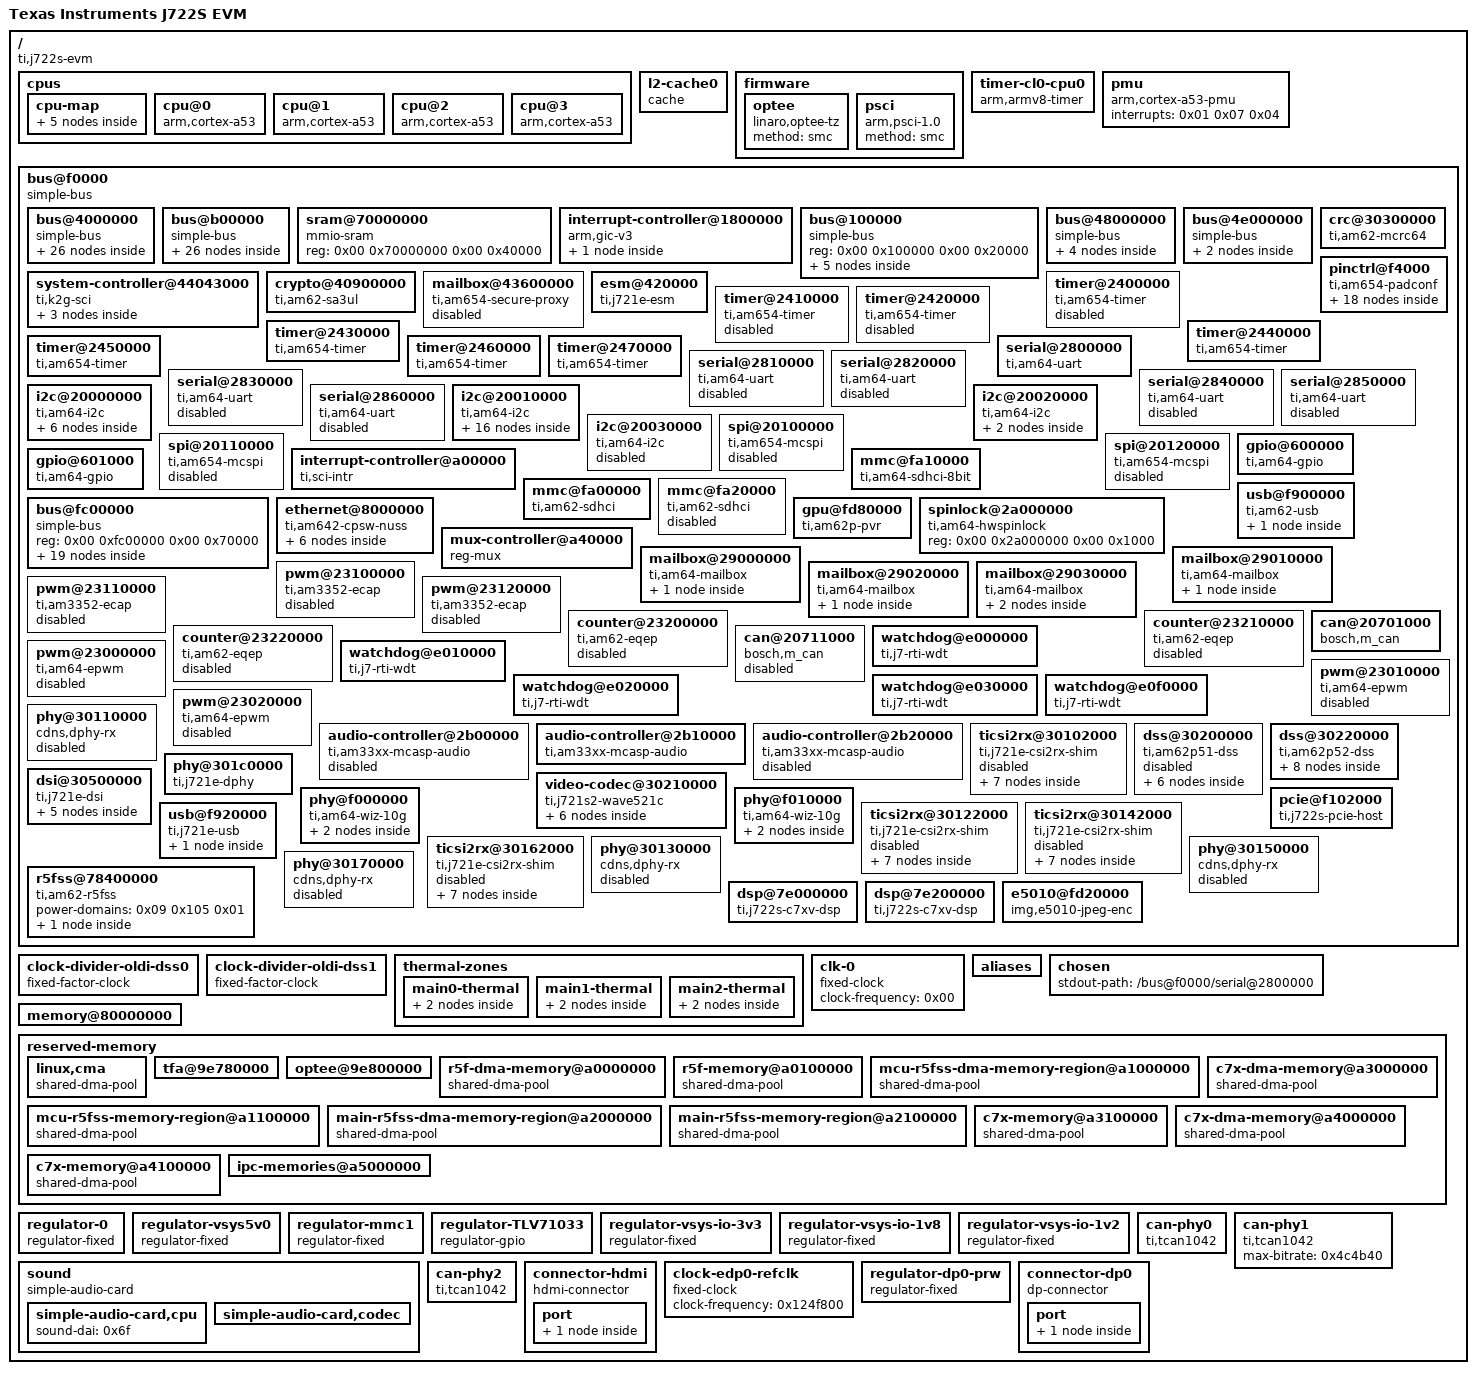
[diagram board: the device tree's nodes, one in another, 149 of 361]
/dts-v1/;

/ {
	model = "Texas Instruments J722S EVM";
	compatible = "ti,j722s-evm\0ti,j722s";
	interrupt-parent = <0x01>;
	#address-cells = <0x02>;
	#size-cells = <0x02>;

	cpus {
		#address-cells = <0x01>;
		#size-cells = <0x00>;

		cpu-map {

			cluster0 {
				phandle = <0x77>;

				core0 {
					cpu = <0x02>;
				};

				core1 {
					cpu = <0x03>;
				};

				core2 {
					cpu = <0x04>;
				};

				core3 {
					cpu = <0x05>;
				};
			};
		};

		cpu@0 {
			compatible = "arm,cortex-a53";
			reg = <0x00>;
			device_type = "cpu";
			enable-method = "psci";
			i-cache-size = <0x8000>;
			i-cache-line-size = <0x40>;
			i-cache-sets = <0x100>;
			d-cache-size = <0x8000>;
			d-cache-line-size = <0x40>;
			d-cache-sets = <0x80>;
			next-level-cache = <0x06>;
			clocks = <0x07 0x87 0x00>;
			phandle = <0x02>;
		};

		cpu@1 {
			compatible = "arm,cortex-a53";
			reg = <0x01>;
			device_type = "cpu";
			enable-method = "psci";
			i-cache-size = <0x8000>;
			i-cache-line-size = <0x40>;
			i-cache-sets = <0x100>;
			d-cache-size = <0x8000>;
			d-cache-line-size = <0x40>;
			d-cache-sets = <0x80>;
			next-level-cache = <0x06>;
			clocks = <0x07 0x88 0x00>;
			phandle = <0x03>;
		};

		cpu@2 {
			compatible = "arm,cortex-a53";
			reg = <0x02>;
			device_type = "cpu";
			enable-method = "psci";
			i-cache-size = <0x8000>;
			i-cache-line-size = <0x40>;
			i-cache-sets = <0x100>;
			d-cache-size = <0x8000>;
			d-cache-line-size = <0x40>;
			d-cache-sets = <0x80>;
			next-level-cache = <0x06>;
			clocks = <0x07 0x89 0x00>;
			phandle = <0x04>;
		};

		cpu@3 {
			compatible = "arm,cortex-a53";
			reg = <0x03>;
			device_type = "cpu";
			enable-method = "psci";
			i-cache-size = <0x8000>;
			i-cache-line-size = <0x40>;
			i-cache-sets = <0x100>;
			d-cache-size = <0x8000>;
			d-cache-line-size = <0x40>;
			d-cache-sets = <0x80>;
			next-level-cache = <0x06>;
			clocks = <0x07 0x8a 0x00>;
			phandle = <0x05>;
		};
	};

	l2-cache0 {
		compatible = "cache";
		cache-unified;
		cache-level = <0x02>;
		cache-size = <0x80000>;
		cache-line-size = <0x40>;
		cache-sets = <0x200>;
		phandle = <0x06>;
	};

	firmware {

		optee {
			compatible = "linaro,optee-tz";
			method = "smc";
		};

		psci {
			compatible = "arm,psci-1.0";
			method = "smc";
			phandle = <0x78>;
		};
	};

	timer-cl0-cpu0 {
		compatible = "arm,armv8-timer";
		interrupts = <0x01 0x0d 0x08 0x01 0x0e 0x08 0x01 0x0b 0x08 0x01 0x0a 0x08>;
		phandle = <0x79>;
	};

	pmu {
		compatible = "arm,cortex-a53-pmu";
		interrupts = <0x01 0x07 0x04>;
		phandle = <0x7a>;
	};

	bus@f0000 {
		compatible = "simple-bus";
		#address-cells = <0x02>;
		#size-cells = <0x02>;
		ranges = <0x00 0xf0000 0x00 0xf0000 0x00 0x30000 0x00 0x420000 0x00 0x420000 0x00 0x1000 0x00 0x600000 0x00 0x600000 0x00 0x1100 0x00 0x703000 0x00 0x703000 0x00 0x200 0x00 0x70c000 0x00 0x70c000 0x00 0x200 0x00 0xa40000 0x00 0xa40000 0x00 0x800 0x00 0x1000000 0x00 0x1000000 0x00 0x1b28400 0x00 0x8000000 0x00 0x8000000 0x00 0x200000 0x00 0xd000000 0x00 0xd000000 0x00 0x800000 0x00 0xe000000 0x00 0xe000000 0x00 0x1d20000 0x00 0xfd80000 0x00 0xfd80000 0x00 0x80000 0x00 0xfd20000 0x00 0xfd20000 0x00 0x100 0x00 0xfd20200 0x00 0xfd20200 0x00 0x200 0x00 0x20000000 0x00 0x20000000 0x00 0xa008000 0x00 0x30040000 0x00 0x30040000 0x00 0x80000 0x00 0x301c0000 0x00 0x301c0000 0x00 0x1000 0x00 0x30101000 0x00 0x30101000 0x00 0x80100 0x00 0x30200000 0x00 0x30200000 0x00 0x10000 0x00 0x30210000 0x00 0x30210000 0x00 0x10000 0x00 0x30220000 0x00 0x30220000 0x00 0x10000 0x00 0x30270000 0x00 0x30270000 0x00 0x10000 0x00 0x30300000 0x00 0x30300000 0x00 0x1000 0x00 0x30500000 0x00 0x30500000 0x00 0x100000 0x00 0x31000000 0x00 0x31000000 0x00 0x50000 0x00 0x31200000 0x00 0x31200000 0x00 0x40000 0x00 0x40900000 0x00 0x40900000 0x00 0x30000 0x00 0x43600000 0x00 0x43600000 0x00 0x10000 0x00 0x44043000 0x00 0x44043000 0x00 0xfe0 0x00 0x44860000 0x00 0x44860000 0x00 0x40000 0x00 0x48000000 0x00 0x48000000 0x00 0x6408000 0x00 0x60000000 0x00 0x60000000 0x00 0x8000000 0x00 0x68000000 0x00 0x68000000 0x00 0x8000000 0x00 0x70000000 0x00 0x70000000 0x00 0x40000 0x00 0x78400000 0x00 0x78400000 0x00 0x8000 0x00 0x78500000 0x00 0x78500000 0x00 0x8000 0x00 0x7e000000 0x00 0x7e000000 0x00 0x200000 0x00 0x7e200000 0x00 0x7e200000 0x00 0x200000 0x01 0x00 0x01 0x00 0x00 0x310000 0x05 0x00 0x05 0x00 0x01 0x00 0x06 0x00 0x06 0x00 0x01 0x00 0x00 0x4000000 0x00 0x4000000 0x00 0x1ff1400 0x00 0x79000000 0x00 0x79000000 0x00 0x8000 0x00 0x79020000 0x00 0x79020000 0x00 0x8000 0x00 0x79100000 0x00 0x79100000 0x00 0x40000 0x00 0x79140000 0x00 0x79140000 0x00 0x40000 0x00 0xb00000 0x00 0xb00000 0x00 0x2400 0x00 0x2b000000 0x00 0x2b000000 0x00 0x300400 0x00 0x43000000 0x00 0x43000000 0x00 0x20000 0x00 0x78000000 0x00 0x78000000 0x00 0x8000 0x00 0x78100000 0x00 0x78100000 0x00 0x8000>;
		phandle = <0x7b>;

		bus@4000000 {
			compatible = "simple-bus";
			#address-cells = <0x02>;
			#size-cells = <0x02>;
			ranges = <0x00 0x4000000 0x00 0x4000000 0x00 0x1ff1400 0x00 0x79000000 0x00 0x79000000 0x00 0x8000 0x00 0x79020000 0x00 0x79020000 0x00 0x8000 0x00 0x79100000 0x00 0x79100000 0x00 0x40000 0x00 0x79140000 0x00 0x79140000 0x00 0x40000>;
			bootph-all;
			phandle = <0x7c>;

			sram@79100000 {
				compatible = "mmio-sram";
				reg = <0x00 0x79100000 0x00 0x80000>;
				ranges = <0x00 0x00 0x79100000 0x80000>;
				#address-cells = <0x01>;
				#size-cells = <0x01>;
				phandle = <0x13>;

				mcu_sram1@0 {
					reg = <0x00 0x80000>;
				};
			};

			pinctrl@4084000 {
				compatible = "pinctrl-single";
				reg = <0x00 0x4084000 0x00 0x88>;
				#pinctrl-cells = <0x01>;
				pinctrl-single,register-width = <0x20>;
				pinctrl-single,function-mask = <0xffffffff>;
				pinctrl-single,gpio-range = <0x08 0x00 0x15 0x54007 0x08 0x17 0x01 0x54007 0x08 0x20 0x02 0x54007>;
				bootph-all;
				phandle = <0x0d>;

				gpio-range {
					#pinctrl-single,gpio-range-cells = <0x03>;
					phandle = <0x08>;
				};

				mcu-i2c0-default-pins {
					pinctrl-single,pins = <0x48 0x54000 0x44 0x54000>;
					phandle = <0x0a>;
				};

				mcu-mcan0-default-pins {
					pinctrl-single,pins = <0x38 0x54000 0x34 0x10000>;
					phandle = <0x0e>;
				};

				mcu-mcan1-default-pins {
					pinctrl-single,pins = <0x40 0x54000 0x3c 0x10000>;
					phandle = <0x10>;
				};

				mcu-mcan0-gpio-default-pins {
					pinctrl-single,pins = <0x30 0x10007>;
					phandle = <0x72>;
				};

				wkup-uart0-default-pins {
					pinctrl-single,pins = <0x2c 0x54000 0x30 0x10000 0x24 0x54000 0x28 0x10000>;
					bootph-all;
					phandle = <0x18>;
				};

				wkup-i2c0-default-pins {
					pinctrl-single,pins = <0x4c 0x64000 0x50 0x64000>;
					bootph-all;
					phandle = <0x19>;
				};
			};

			esm@4100000 {
				compatible = "ti,j721e-esm";
				reg = <0x00 0x4100000 0x00 0x1000>;
				bootph-pre-ram;
				ti,esm-pins = <0x00 0x01 0x02 0x55 0x56>;
				phandle = <0x7d>;
			};

			timer@4800000 {
				compatible = "ti,am654-timer";
				reg = <0x00 0x4800000 0x00 0x400>;
				clocks = <0x07 0x23 0x02>;
				clock-names = "fck";
				power-domains = <0x09 0x23 0x01>;
				ti,timer-pwm;
				status = "reserved";
				phandle = <0x7e>;
			};

			timer@4810000 {
				compatible = "ti,am654-timer";
				reg = <0x00 0x4810000 0x00 0x400>;
				clocks = <0x07 0x30 0x02>;
				clock-names = "fck";
				power-domains = <0x09 0x30 0x01>;
				ti,timer-pwm;
				status = "reserved";
				phandle = <0x7f>;
			};

			timer@4820000 {
				compatible = "ti,am654-timer";
				reg = <0x00 0x4820000 0x00 0x400>;
				clocks = <0x07 0x31 0x02>;
				clock-names = "fck";
				power-domains = <0x09 0x31 0x01>;
				ti,timer-pwm;
				status = "reserved";
				phandle = <0x80>;
			};

			timer@4830000 {
				compatible = "ti,am654-timer";
				reg = <0x00 0x4830000 0x00 0x400>;
				clocks = <0x07 0x32 0x02>;
				clock-names = "fck";
				power-domains = <0x09 0x32 0x01>;
				ti,timer-pwm;
				status = "reserved";
				phandle = <0x81>;
			};

			serial@4a00000 {
				compatible = "ti,am64-uart\0ti,am654-uart";
				reg = <0x00 0x4a00000 0x00 0x100>;
				interrupts = <0x00 0xb9 0x04>;
				power-domains = <0x09 0x95 0x01>;
				clocks = <0x07 0x95 0x00>;
				clock-names = "fclk";
				status = "disabled";
				phandle = <0x82>;
			};

			i2c@4900000 {
				compatible = "ti,am64-i2c\0ti,omap4-i2c";
				reg = <0x00 0x4900000 0x00 0x100>;
				interrupts = <0x00 0x6b 0x04>;
				#address-cells = <0x01>;
				#size-cells = <0x00>;
				power-domains = <0x09 0x6a 0x01>;
				clocks = <0x07 0x6a 0x02>;
				clock-names = "fck";
				status = "okay";
				pinctrl-names = "default";
				pinctrl-0 = <0x0a>;
				clock-frequency = <0x61a80>;
				phandle = <0x83>;
			};

			spi@4b00000 {
				compatible = "ti,am654-mcspi\0ti,omap4-mcspi";
				reg = <0x00 0x4b00000 0x00 0x400>;
				interrupts = <0x00 0xb0 0x04>;
				#address-cells = <0x01>;
				#size-cells = <0x00>;
				power-domains = <0x09 0x93 0x01>;
				clocks = <0x07 0x93 0x00>;
				status = "disabled";
				phandle = <0x84>;
			};

			spi@4b10000 {
				compatible = "ti,am654-mcspi\0ti,omap4-mcspi";
				reg = <0x00 0x4b10000 0x00 0x400>;
				interrupts = <0x00 0xb1 0x04>;
				#address-cells = <0x01>;
				#size-cells = <0x00>;
				power-domains = <0x09 0x94 0x01>;
				clocks = <0x07 0x94 0x00>;
				status = "disabled";
				phandle = <0x85>;
			};

			interrupt-controller@4210000 {
				compatible = "ti,sci-intr";
				reg = <0x00 0x4210000 0x00 0x200>;
				ti,intr-trigger-type = <0x01>;
				interrupt-controller;
				interrupt-parent = <0x01>;
				#interrupt-cells = <0x01>;
				ti,sci = <0x0b>;
				ti,sci-dev-id = <0x05>;
				ti,interrupt-ranges = <0x00 0x68 0x04>;
				phandle = <0x0c>;
			};

			gpio@4201000 {
				compatible = "ti,am64-gpio\0ti,keystone-gpio";
				reg = <0x00 0x4201000 0x00 0x100>;
				gpio-controller;
				#gpio-cells = <0x02>;
				interrupt-parent = <0x0c>;
				interrupts = <0x1e 0x1f>;
				interrupt-controller;
				#interrupt-cells = <0x02>;
				ti,ngpio = <0x18>;
				ti,davinci-gpio-unbanked = <0x00>;
				power-domains = <0x09 0x4f 0x01>;
				clocks = <0x07 0x4f 0x00>;
				clock-names = "gpio";
				gpio-ranges = <0x0d 0x00 0x00 0x15 0x0d 0x15 0x17 0x01 0x0d 0x16 0x20 0x02>;
				status = "okay";
				phandle = <0x73>;
			};

			watchdog@4880000 {
				compatible = "ti,j7-rti-wdt";
				reg = <0x00 0x4880000 0x00 0x100>;
				clocks = <0x07 0x83 0x00>;
				power-domains = <0x09 0x83 0x01>;
				assigned-clocks = <0x07 0x83 0x00>;
				assigned-clock-parents = <0x07 0x83 0x04>;
				status = "reserved";
				phandle = <0x86>;
			};

			can@4e08000 {
				compatible = "bosch,m_can";
				reg = <0x00 0x4e08000 0x00 0x200 0x00 0x4e00000 0x00 0x8000>;
				reg-names = "m_can\0message_ram";
				power-domains = <0x09 0xbc 0x01>;
				clocks = <0x07 0xbc 0x06 0x07 0xbc 0x01>;
				clock-names = "hclk\0cclk";
				bosch,mram-cfg = <0x00 0x80 0x40 0x40 0x40 0x40 0x20 0x20>;
				interrupts = <0x00 0x1a 0x04 0x00 0x1b 0x04>;
				interrupt-names = "int0\0int1";
				wakeup-source = "suspend\0poweroff";
				status = "okay";
				pinctrl-names = "default";
				pinctrl-0 = <0x0e>;
				phys = <0x0f>;
				phandle = <0x87>;
			};

			can@4e18000 {
				compatible = "bosch,m_can";
				reg = <0x00 0x4e18000 0x00 0x200 0x00 0x4e10000 0x00 0x8000>;
				reg-names = "m_can\0message_ram";
				power-domains = <0x09 0xbd 0x01>;
				clocks = <0x07 0xbd 0x06 0x07 0xbd 0x01>;
				clock-names = "hclk\0cclk";
				bosch,mram-cfg = <0x00 0x80 0x40 0x40 0x40 0x40 0x20 0x20>;
				interrupts = <0x00 0x1c 0x04 0x00 0x1d 0x04>;
				interrupt-names = "int0\0int1";
				wakeup-source = "suspend\0poweroff";
				status = "okay";
				pinctrl-names = "default";
				pinctrl-0 = <0x10>;
				phys = <0x11>;
				phandle = <0x88>;
			};

			r5fss@79000000 {
				compatible = "ti,am62-r5fss";
				#address-cells = <0x01>;
				#size-cells = <0x01>;
				ranges = <0x79000000 0x00 0x79000000 0x8000 0x79020000 0x00 0x79020000 0x8000>;
				power-domains = <0x09 0x07 0x01>;
				status = "disabled";
				phandle = <0x89>;

				r5f@79000000 {
					compatible = "ti,am62-r5f";
					reg = <0x79000000 0x8000 0x79020000 0x8000>;
					reg-names = "atcm\0btcm";
					ti,sci = <0x0b>;
					ti,sci-dev-id = <0x09>;
					ti,sci-proc-ids = <0x03 0xff>;
					resets = <0x12 0x09 0x01>;
					firmware-name = "j722s-mcu-r5f0_0-fw";
					ti,atcm-enable = <0x00>;
					ti,btcm-enable = <0x01>;
					ti,loczrama = <0x00>;
					sram = <0x13>;
					status = "disabled";
					mboxes = <0x14 0x15>;
					memory-region = <0x16 0x17>;
					phandle = <0x8a>;
				};
			};
		};

		bus@b00000 {
			compatible = "simple-bus";
			#address-cells = <0x02>;
			#size-cells = <0x02>;
			ranges = <0x00 0xb00000 0x00 0xb00000 0x00 0x2400 0x00 0x2b000000 0x00 0x2b000000 0x00 0x300400 0x00 0x43000000 0x00 0x43000000 0x00 0x20000 0x00 0x78000000 0x00 0x78000000 0x00 0x8000 0x00 0x78100000 0x00 0x78100000 0x00 0x8000>;
			bootph-all;
			phandle = <0x8b>;

			bus@43000000 {
				compatible = "simple-bus";
				reg = <0x00 0x43000000 0x00 0x20000>;
				#address-cells = <0x01>;
				#size-cells = <0x01>;
				ranges = <0x00 0x00 0x43000000 0x20000>;
				bootph-all;
				phandle = <0x8c>;

				chipid@14 {
					compatible = "ti,am654-chipid";
					reg = <0x14 0x04>;
					bootph-all;
					phandle = <0x8d>;
				};

				syscon@18 {
					compatible = "ti,am62-opp-efuse-table\0syscon";
					reg = <0x18 0x04>;
					phandle = <0x8e>;
				};

				ethernet-mac-syscon@200 {
					compatible = "ti,am62p-cpsw-mac-efuse\0syscon";
					reg = <0x200 0x08>;
					phandle = <0x40>;
				};

				syscon@4008 {
					compatible = "ti,am62-usb-phy-ctrl\0syscon";
					reg = <0x4008 0x04>;
					phandle = <0x3c>;
				};

				syscon@4018 {
					compatible = "ti,am62-usb-phy-ctrl\0syscon";
					reg = <0x4018 0x04>;
					phandle = <0x8f>;
				};

				syscon@80d0 {
					compatible = "ti,am62-ddr-pmctrl\0syscon";
					reg = <0x80d0 0x04>;
					phandle = <0x90>;
				};

				syscon@18300 {
					compatible = "ti,am62-canuart-wake\0syscon";
					reg = <0x18300 0x44>;
					phandle = <0x91>;
				};

				pcie0-ctrl@4070 {
					compatible = "ti,j784s4-pcie-ctrl\0syscon";
					reg = <0x4070 0x04>;
					phandle = <0x56>;
				};
			};

			target-module@2b300050 {
				compatible = "ti,sysc-omap2\0ti,sysc";
				reg = <0x00 0x2b300050 0x00 0x04 0x00 0x2b300054 0x00 0x04 0x00 0x2b300058 0x00 0x04>;
				reg-names = "rev\0sysc\0syss";
				ti,sysc-mask = <0x07>;
				ti,sysc-sidle = <0x00 0x01 0x02 0x03>;
				ti,syss-mask = <0x01>;
				ti,no-reset-on-init;
				power-domains = <0x09 0x72 0x01>;
				clocks = <0x07 0x72 0x00>;
				clock-names = "fck";
				#address-cells = <0x01>;
				#size-cells = <0x01>;
				ranges = <0x00 0x00 0x2b300000 0x100000>;

				serial@0 {
					compatible = "ti,am64-uart\0ti,am654-uart";
					reg = <0x00 0x100>;
					interrupts = <0x00 0xba 0x04>;
					status = "reserved";
					pinctrl-names = "default";
					pinctrl-0 = <0x18>;
					bootph-all;
					phandle = <0x92>;
				};
			};

			i2c@2b200000 {
				compatible = "ti,am64-i2c\0ti,omap4-i2c";
				reg = <0x00 0x2b200000 0x00 0x100>;
				interrupts = <0x00 0xa5 0x04>;
				#address-cells = <0x01>;
				#size-cells = <0x00>;
				power-domains = <0x09 0x6b 0x01>;
				clocks = <0x07 0x6b 0x04>;
				clock-names = "fck";
				status = "okay";
				pinctrl-names = "default";
				pinctrl-0 = <0x19>;
				clock-frequency = <0x61a80>;
				bootph-all;
				phandle = <0x93>;

				pmic@48 {
					compatible = "ti,tps65224-q1";
					reg = <0x48>;
					pinctrl-names = "default";
					pinctrl-0 = <0x1a>;
					interrupt-parent = <0x1b>;
					interrupts = <0x00 0x02>;
					ti,primary-pmic;
					gpio-controller;
					#gpio-cells = <0x02>;
					buck12-supply = <0x1c>;
					buck3-supply = <0x1c>;
					buck4-supply = <0x1c>;
					ldo1-supply = <0x1c>;
					ldo2-supply = <0x1c>;
					ldo3-supply = <0x1c>;
					phandle = <0x94>;

					regulators {

						buck1 {
							regulator-name = "vcc1v8_io_buck1";
							regulator-min-microvolt = <0x1b7740>;
							regulator-max-microvolt = <0x1b7740>;
							regulator-boot-on;
							regulator-always-on;
							bootph-all;
							phandle = <0x95>;
						};

						buck2 {
							regulator-name = "vcc1v1_ddr_buck2";
							regulator-min-microvolt = <0x10c8e0>;
							regulator-max-microvolt = <0x10c8e0>;
							regulator-boot-on;
							regulator-always-on;
							phandle = <0x96>;
						};

						buck3 {
							regulator-name = "vcc0v85_ram_buck3";
							regulator-min-microvolt = <0xcf850>;
							regulator-max-microvolt = <0xcf850>;
							regulator-boot-on;
							regulator-always-on;
							phandle = <0x97>;
						};

						buck4 {
							regulator-name = "vcc0v75_ioret_buck4";
							regulator-min-microvolt = <0xb71b0>;
							regulator-max-microvolt = <0xb71b0>;
							regulator-boot-on;
							regulator-always-on;
							phandle = <0x98>;
						};

						ldo1 {
							regulator-name = "vdda1v8_pll_ldo1";
							regulator-min-microvolt = <0x1b7740>;
							regulator-max-microvolt = <0x1b7740>;
							regulator-boot-on;
							regulator-always-on;
							phandle = <0x99>;
						};

						ldo2 {
							regulator-name = "dvdd3v3_ldo2";
							regulator-min-microvolt = <0x325aa0>;
							regulator-max-microvolt = <0x325aa0>;
							regulator-boot-on;
							regulator-always-on;
							phandle = <0x9a>;
						};

						ldo3 {
							regulator-name = "vdd1v85_phy_ldo3";
							regulator-min-microvolt = <0x1b7740>;
							regulator-max-microvolt = <0x1b7740>;
							regulator-boot-on;
							regulator-always-on;
							phandle = <0x9b>;
						};
					};
				};
			};

			rtc@2b1f0000 {
				compatible = "ti,am62-rtc";
				reg = <0x00 0x2b1f0000 0x00 0x100>;
				interrupts = <0x00 0x64 0x04>;
				clocks = <0x07 0x75 0x06 0x07 0x75 0x00>;
				clock-names = "vbus\0osc32k";
				power-domains = <0x09 0x75 0x01>;
				wakeup-source;
				phandle = <0x9c>;
			};

			watchdog@2b000000 {
				compatible = "ti,j7-rti-wdt";
				reg = <0x00 0x2b000000 0x00 0x100>;
				clocks = <0x07 0x84 0x00>;
				power-domains = <0x09 0x84 0x01>;
				assigned-clocks = <0x07 0x84 0x00>;
				assigned-clock-parents = <0x07 0x84 0x02>;
				status = "reserved";
				phandle = <0x9d>;
			};

			temperature-sensor@b00000 {
				compatible = "ti,j7200-vtm";
				reg = <0x00 0xb00000 0x00 0x400 0x00 0xb01000 0x00 0x400>;
				power-domains = <0x09 0x5f 0x01>;
				#thermal-sensor-cells = <0x01>;
				phandle = <0x6a>;
			};

			r5fss@78000000 {
				compatible = "ti,am62-r5fss";
				#address-cells = <0x01>;
				#size-cells = <0x01>;
				ranges = <0x78000000 0x00 0x78000000 0x8000 0x78100000 0x00 0x78100000 0x8000>;
				power-domains = <0x09 0x77 0x01>;
				status = "okay";
				phandle = <0x9e>;

				r5f@78000000 {
					compatible = "ti,am62-r5f";
					reg = <0x78000000 0x8000 0x78100000 0x8000>;
					reg-names = "atcm\0btcm";
					ti,sci = <0x0b>;
					ti,sci-dev-id = <0x79>;
					ti,sci-proc-ids = <0x01 0xff>;
					resets = <0x12 0x79 0x01>;
					firmware-name = "j722s-wkup-r5f0_0-fw";
					ti,atcm-enable = <0x01>;
					ti,btcm-enable = <0x01>;
					ti,loczrama = <0x01>;
					mboxes = <0x1d 0x1e>;
					memory-region = <0x1f 0x20>;
					phandle = <0x9f>;
				};
			};
		};

		sram@70000000 {
			compatible = "mmio-sram";
			#address-cells = <0x01>;
			#size-cells = <0x01>;
			reg = <0x00 0x70000000 0x00 0x40000>;
			ranges = <0x00 0x00 0x70000000 0x40000>;
			phandle = <0x50>;
		};

		interrupt-controller@1800000 {
			compatible = "arm,gic-v3";
			#address-cells = <0x02>;
			#size-cells = <0x02>;
			ranges;
			#interrupt-cells = <0x03>;
			interrupt-controller;
			reg = <0x00 0x1800000 0x00 0x10000 0x00 0x1880000 0x00 0xc0000 0x01 0x00 0x00 0x2000 0x01 0x10000 0x00 0x1000 0x01 0x20000 0x00 0x2000>;
			interrupts = <0x01 0x09 0x04>;
			phandle = <0x01>;

			msi-controller@1820000 {
				compatible = "arm,gic-v3-its";
				reg = <0x00 0x1820000 0x00 0x10000>;
				socionext,synquacer-pre-its = <0x1000000 0x400000>;
				msi-controller;
				#msi-cells = <0x01>;
				phandle = <0x57>;
			};
		};

		bus@100000 {
			compatible = "simple-bus";
			reg = <0x00 0x100000 0x00 0x20000>;
			#address-cells = <0x01>;
			#size-cells = <0x01>;
			ranges = <0x00 0x00 0x100000 0x20000>;
			phandle = <0xa0>;

			phy@4044 {
				compatible = "ti,am654-phy-gmii-sel";
				reg = <0x4044 0x08>;
				#phy-cells = <0x01>;
				bootph-all;
				phandle = <0x3f>;
			};

			clock-controller@4130 {
				compatible = "ti,am62-epwm-tbclk";
				reg = <0x4130 0x04>;
				#clock-cells = <0x01>;
				phandle = <0x45>;
			};

			dss-oldi-io-ctrl@8600 {
				compatible = "syscon";
				reg = <0x8600 0x200>;
				phandle = <0x49>;
			};

			mux-controller@4080 {
				compatible = "reg-mux";
				reg = <0x4080 0x14>;
				#mux-control-cells = <0x01>;
				mux-reg-masks = <0x00 0x03 0x10 0x03>;
				idle-states = <0x00 0x00>;
				phandle = <0xa1>;
			};

			clock@82e4 {
				compatible = "ti,am62-audio-refclk";
				reg = <0x82e4 0x04>;
				clocks = <0x07 0x9d 0x12>;
				assigned-clocks = <0x07 0x9d 0x12>;
				assigned-clock-parents = <0x07 0x9d 0x21>;
				#clock-cells = <0x00>;
				phandle = <0x71>;
			};
		};

		bus@48000000 {
			compatible = "simple-bus";
			#address-cells = <0x02>;
			#size-cells = <0x02>;
			dma-ranges;
			ranges = <0x00 0x48000000 0x00 0x48000000 0x00 0x6400000>;
			bootph-all;
			ti,sci-dev-id = <0x19>;
			phandle = <0xa2>;

			mailbox@4d000000 {
				compatible = "ti,am654-secure-proxy";
				#mbox-cells = <0x01>;
				reg-names = "target_data\0rt\0scfg";
				reg = <0x00 0x4d000000 0x00 0x80000 0x00 0x4a600000 0x00 0x80000 0x00 0x4a400000 0x00 0x80000>;
				interrupt-names = "rx_012";
				interrupts = <0x00 0x22 0x04>;
				bootph-all;
				phandle = <0x26>;
			};

			interrupt-controller@48000000 {
				compatible = "ti,sci-inta";
				reg = <0x00 0x48000000 0x00 0x100000>;
				#interrupt-cells = <0x00>;
				interrupt-controller;
				interrupt-parent = <0x01>;
				msi-controller;
				ti,sci = <0x0b>;
				ti,sci-dev-id = <0x1c>;
				ti,unmapped-event-sources = <0x21 0x22>;
				ti,interrupt-ranges = <0x07 0x47 0x15>;
				phandle = <0x23>;
			};

			dma-controller@485c0100 {
				compatible = "ti,am64-dmss-bcdma";
				reg = <0x00 0x485c0100 0x00 0x100 0x00 0x4c000000 0x00 0x20000 0x00 0x4a820000 0x00 0x20000 0x00 0x4aa40000 0x00 0x20000 0x00 0x4bc00000 0x00 0x100000 0x00 0x48600000 0x00 0x8000 0x00 0x484a4000 0x00 0x2000 0x00 0x484c2000 0x00 0x2000 0x00 0x48420000 0x00 0x2000>;
				reg-names = "gcfg\0bchanrt\0rchanrt\0tchanrt\0ringrt\0ring\0tchan\0rchan\0bchan";
				msi-parent = <0x23>;
				#dma-cells = <0x03>;
				ti,sci = <0x0b>;
				ti,sci-dev-id = <0x1a>;
				ti,sci-rm-range-bchan = <0x20>;
				ti,sci-rm-range-rchan = <0x21>;
				ti,sci-rm-range-tchan = <0x22>;
				bootph-all;
				phandle = <0x21>;
			};

			dma-controller@485c0000 {
				compatible = "ti,am64-dmss-pktdma";
				reg = <0x00 0x485c0000 0x00 0x100 0x00 0x4a800000 0x00 0x20000 0x00 0x4aa00000 0x00 0x20000 0x00 0x4b800000 0x00 0x200000 0x00 0x485e0000 0x00 0x10000 0x00 0x484a0000 0x00 0x2000 0x00 0x484c0000 0x00 0x2000 0x00 0x48430000 0x00 0x1000>;
				reg-names = "gcfg\0rchanrt\0tchanrt\0ringrt\0ring\0tchan\0rchan\0rflow";
				msi-parent = <0x23>;
				#dma-cells = <0x02>;
				bootph-all;
				ti,sci = <0x0b>;
				ti,sci-dev-id = <0x1e>;
				ti,sci-rm-range-tchan = <0x23 0x24 0x25 0x26>;
				ti,sci-rm-range-tflow = <0x10 0x11 0x12 0x13>;
				ti,sci-rm-range-rchan = <0x29 0x2b 0x2d 0x2f 0x31 0x33>;
				ti,sci-rm-range-rflow = <0x2a 0x2c 0x2e 0x32>;
				phandle = <0x22>;
			};
		};

		bus@4e000000 {
			compatible = "simple-bus";
			ranges = <0x00 0x4e000000 0x00 0x4e000000 0x00 0x408000>;
			#address-cells = <0x02>;
			#size-cells = <0x02>;
			dma-ranges;
			ti,sci-dev-id = <0xc6>;
			phandle = <0xa3>;

			interrupt-controller@4e400000 {
				compatible = "ti,sci-inta";
				reg = <0x00 0x4e400000 0x00 0x8000>;
				#interrupt-cells = <0x00>;
				interrupt-controller;
				interrupt-parent = <0x01>;
				msi-controller;
				power-domains = <0x09 0xb6 0x01>;
				ti,sci = <0x0b>;
				ti,sci-dev-id = <0xc8>;
				ti,interrupt-ranges = <0x00 0xed 0x08>;
				ti,unmapped-event-sources = <0x24>;
				phandle = <0x25>;
			};

			dma-controller@4e230000 {
				compatible = "ti,j722s-dmss-bcdma-csi";
				reg = <0x00 0x4e230000 0x00 0x100 0x00 0x4e180000 0x00 0x20000 0x00 0x4e300000 0x00 0x10000 0x00 0x4e100000 0x00 0x80000>;
				reg-names = "gcfg\0rchanrt\0tchanrt\0ringrt";
				#dma-cells = <0x03>;
				msi-parent = <0x25>;
				power-domains = <0x09 0xb6 0x01>;
				ti,sci = <0x0b>;
				ti,sci-dev-id = <0xc7>;
				ti,sci-rm-range-rchan = <0x21>;
				ti,sci-rm-range-tchan = <0x22>;
				phandle = <0x24>;
			};
		};

		system-controller@44043000 {
			compatible = "ti,k2g-sci";
			ti,host-id = <0x0c>;
			mbox-names = "rx\0tx";
			mboxes = <0x26 0x0c 0x26 0x0d>;
			reg-names = "debug_messages";
			reg = <0x00 0x44043000 0x00 0xfe0>;
			bootph-all;
			phandle = <0x0b>;

			power-controller {
				compatible = "ti,sci-pm-domain";
				#power-domain-cells = <0x02>;
				bootph-all;
				phandle = <0x09>;
			};

			clock-controller {
				compatible = "ti,k2g-sci-clk";
				#clock-cells = <0x02>;
				bootph-all;
				pinctrl-names = "default";
				pinctrl-0 = <0x27>;
				phandle = <0x07>;
			};

			reset-controller {
				compatible = "ti,sci-reset";
				#reset-cells = <0x02>;
				bootph-all;
				phandle = <0x12>;
			};
		};

		crypto@40900000 {
			compatible = "ti,am62-sa3ul";
			reg = <0x00 0x40900000 0x00 0x1200>;
			#address-cells = <0x02>;
			#size-cells = <0x02>;
			dmas = <0x22 0xf501 0x00 0x22 0x7506 0x00 0x22 0x7507 0x00>;
			dma-names = "tx\0rx1\0rx2";
			phandle = <0xa4>;
		};

		crc@30300000 {
			compatible = "ti,am62-mcrc64";
			reg = <0x00 0x30300000 0x00 0x1000>;
			clocks = <0x07 0x74 0x00>;
			power-domains = <0x09 0x74 0x01>;
			phandle = <0xa5>;
		};

		mailbox@43600000 {
			compatible = "ti,am654-secure-proxy";
			#mbox-cells = <0x01>;
			reg-names = "target_data\0rt\0scfg";
			reg = <0x00 0x43600000 0x00 0x10000 0x00 0x44880000 0x00 0x20000 0x00 0x44860000 0x00 0x20000>;
			status = "disabled";
			bootph-all;
			phandle = <0xa6>;
		};

		pinctrl@f4000 {
			compatible = "ti,am654-padconf\0pinctrl-single";
			reg = <0x00 0xf4000 0x00 0x2ac>;
			#pinctrl-cells = <0x01>;
			pinctrl-single,register-width = <0x20>;
			pinctrl-single,function-mask = <0xffffffff>;
			interrupt-controller;
			#interrupt-cells = <0x01>;
			bootph-all;
			pinctrl-single,gpio-range = <0x28 0x00 0x20 0x54007 0x28 0x21 0x26 0x54007 0x28 0x48 0x11 0x54007 0x28 0x65 0x19 0x54007 0x28 0x89 0x05 0x54007 0x28 0x8f 0x03 0x54007 0x28 0x95 0x02 0x54007>;
			phandle = <0x38>;

			gpio-range {
				#pinctrl-single,gpio-range-cells = <0x03>;
				phandle = <0x28>;
			};

			main-mcan0-default-pins {
				pinctrl-single,pins = <0x1dc 0x54000 0x1d8 0x10000>;
				phandle = <0x43>;
			};

			main-i2c0-default-pins {
				pinctrl-single,pins = <0x1e0 0x64000 0x1e4 0x64000>;
				bootph-all;
				phandle = <0x2b>;
			};

			main-i2c1-default-pins {
				pinctrl-single,pins = <0x1e8 0x64000 0x1ec 0x64000>;
				bootph-all;
				phandle = <0x2d>;
			};

			main-i2c2-default-pins {
				pinctrl-single,pins = <0xb0 0x64001 0xb4 0x64001>;
				phandle = <0x36>;
			};

			main-uart0-default-pins {
				pinctrl-single,pins = <0x1c8 0x54000 0x1cc 0x10000>;
				bootph-all;
				phandle = <0x29>;
			};

			main-uart5-default-pins {
				pinctrl-single,pins = <0x108 0x54003 0x10c 0x10003>;
				phandle = <0x2a>;
			};

			vdd-sd-dv-default-pins {
				pinctrl-single,pins = <0x120 0x54007>;
				bootph-all;
				phandle = <0x6c>;
			};

			main-mmc1-default-pins {
				pinctrl-single,pins = <0x23c 0x54000 0x234 0x10000 0x230 0x54000 0x22c 0x64000 0x228 0x64000 0x224 0x64000 0x240 0x54000>;
				bootph-all;
				phandle = <0x3b>;
			};

			mdio-default-pins {
				pinctrl-single,pins = <0x160 0x10000 0x15c 0x54000>;
				bootph-all;
				phandle = <0x42>;
			};

			ospi0-default-pins {
				pinctrl-single,pins = <0x00 0x10000 0x2c 0x10000 0x0c 0x54000 0x10 0x54000 0x14 0x54000 0x18 0x54000 0x1c 0x54000 0x20 0x54000 0x24 0x54000 0x28 0x54000 0x08 0x54000>;
				bootph-all;
				phandle = <0x3d>;
			};

			rgmii1-default-pins {
				pinctrl-single,pins = <0x14c 0x54000 0x150 0x54000 0x154 0x54000 0x158 0x54000 0x148 0x54000 0x144 0x54000 0x134 0x10000 0x138 0x10000 0x13c 0x10000 0x140 0x10000 0x130 0x10000 0x12c 0x10000>;
				bootph-all;
				phandle = <0x3e>;
			};

			main-usb1-default-pins {
				pinctrl-single,pins = <0x258 0x54000>;
				phandle = <0x5a>;
			};

			main-mcasp1-default-pins {
				pinctrl-single,pins = <0x90 0x54002 0x98 0x54002 0x8c 0x10002 0x84 0x54002>;
				phandle = <0x46>;
			};

			audio-ext-refclk1-default-pins {
				pinctrl-single,pins = <0xa0 0x10001>;
				phandle = <0x27>;
			};

			pmic-irq-default-pins {
				pinctrl-single,pins = <0x30 0x54007>;
				phandle = <0x1a>;
			};

			main-gpio0-ioexp-intr-default-pins {
				pinctrl-single,pins = <0x110 0x54007>;
				phandle = <0x2e>;
			};

			main-dpi-default-pins {
				pinctrl-single,pins = <0x100 0x10000 0xf8 0x10000 0x104 0x10000 0xfc 0x10000 0xb8 0x10000 0xbc 0x10000 0xc0 0x10000 0xc4 0x10000 0xc8 0x10000 0xcc 0x10000 0xd0 0x10000 0xd4 0x10000 0xd8 0x10000 0xdc 0x10000 0xe0 0x10000 0xe4 0x10000 0xe8 0x10000 0xec 0x10000 0xf0 0x10000 0xf4 0x10000 0x5c 0x10001 0x60 0x10001 0x64 0x10001 0x68 0x10001 0x6c 0x10001 0x70 0x10001 0x74 0x10001 0x78 0x10001 0x9c 0x10001>;
				phandle = <0x4a>;
			};
		};

		esm@420000 {
			compatible = "ti,j721e-esm";
			reg = <0x00 0x420000 0x00 0x1000>;
			bootph-pre-ram;
			ti,esm-pins = <0xe0 0xe1 0xe3 0xf1 0xf2 0xf8>;
			phandle = <0xa7>;
		};

		timer@2400000 {
			compatible = "ti,am654-timer";
			reg = <0x00 0x2400000 0x00 0x400>;
			interrupts = <0x00 0x78 0x04>;
			clocks = <0x07 0x24 0x02>;
			clock-names = "fck";
			assigned-clocks = <0x07 0x24 0x02>;
			assigned-clock-parents = <0x07 0x24 0x03>;
			power-domains = <0x09 0x24 0x01>;
			ti,timer-pwm;
			bootph-all;
			status = "reserved";
			phandle = <0xa8>;
		};

		timer@2410000 {
			compatible = "ti,am654-timer";
			reg = <0x00 0x2410000 0x00 0x400>;
			interrupts = <0x00 0x79 0x04>;
			clocks = <0x07 0x25 0x02>;
			clock-names = "fck";
			assigned-clocks = <0x07 0x25 0x02>;
			assigned-clock-parents = <0x07 0x25 0x03>;
			power-domains = <0x09 0x25 0x01>;
			ti,timer-pwm;
			status = "reserved";
			phandle = <0xa9>;
		};

		timer@2420000 {
			compatible = "ti,am654-timer";
			reg = <0x00 0x2420000 0x00 0x400>;
			interrupts = <0x00 0x7a 0x04>;
			clocks = <0x07 0x26 0x02>;
			clock-names = "fck";
			assigned-clocks = <0x07 0x26 0x02>;
			assigned-clock-parents = <0x07 0x26 0x03>;
			power-domains = <0x09 0x26 0x01>;
			ti,timer-pwm;
			status = "reserved";
			phandle = <0xaa>;
		};

		timer@2430000 {
			compatible = "ti,am654-timer";
			reg = <0x00 0x2430000 0x00 0x400>;
			interrupts = <0x00 0x7b 0x04>;
			clocks = <0x07 0x27 0x02>;
			clock-names = "fck";
			assigned-clocks = <0x07 0x27 0x02>;
			assigned-clock-parents = <0x07 0x27 0x03>;
			power-domains = <0x09 0x27 0x01>;
			ti,timer-pwm;
			phandle = <0xab>;
		};

		timer@2440000 {
			compatible = "ti,am654-timer";
			reg = <0x00 0x2440000 0x00 0x400>;
			interrupts = <0x00 0x7c 0x04>;
			clocks = <0x07 0x28 0x02>;
			clock-names = "fck";
			assigned-clocks = <0x07 0x28 0x02>;
			assigned-clock-parents = <0x07 0x28 0x03>;
			power-domains = <0x09 0x28 0x01>;
			ti,timer-pwm;
			phandle = <0xac>;
		};

		timer@2450000 {
			compatible = "ti,am654-timer";
			reg = <0x00 0x2450000 0x00 0x400>;
			interrupts = <0x00 0x7d 0x04>;
			clocks = <0x07 0x29 0x02>;
			clock-names = "fck";
			assigned-clocks = <0x07 0x29 0x02>;
			assigned-clock-parents = <0x07 0x29 0x03>;
			power-domains = <0x09 0x29 0x01>;
			ti,timer-pwm;
			phandle = <0xad>;
		};

		timer@2460000 {
			compatible = "ti,am654-timer";
			reg = <0x00 0x2460000 0x00 0x400>;
			interrupts = <0x00 0x7e 0x04>;
			clocks = <0x07 0x2a 0x02>;
			clock-names = "fck";
			assigned-clocks = <0x07 0x2a 0x02>;
			assigned-clock-parents = <0x07 0x2a 0x03>;
			power-domains = <0x09 0x2a 0x01>;
			ti,timer-pwm;
			phandle = <0xae>;
		};

		timer@2470000 {
			compatible = "ti,am654-timer";
			reg = <0x00 0x2470000 0x00 0x400>;
			interrupts = <0x00 0x7f 0x04>;
			clocks = <0x07 0x2b 0x02>;
			clock-names = "fck";
			assigned-clocks = <0x07 0x2b 0x02>;
			assigned-clock-parents = <0x07 0x2b 0x03>;
			power-domains = <0x09 0x2b 0x01>;
			ti,timer-pwm;
			phandle = <0xaf>;
		};

		serial@2800000 {
			compatible = "ti,am64-uart\0ti,am654-uart";
			reg = <0x00 0x2800000 0x00 0x100>;
			interrupts = <0x00 0xb2 0x04>;
			power-domains = <0x09 0x92 0x01>;
			clocks = <0x07 0x92 0x00>;
			clock-names = "fclk";
			status = "okay";
			pinctrl-names = "default";
			pinctrl-0 = <0x29>;
			bootph-all;
			phandle = <0xb0>;
		};

		serial@2810000 {
			compatible = "ti,am64-uart\0ti,am654-uart";
			reg = <0x00 0x2810000 0x00 0x100>;
			interrupts = <0x00 0xb3 0x04>;
			power-domains = <0x09 0x98 0x01>;
			clocks = <0x07 0x98 0x00>;
			clock-names = "fclk";
			status = "disabled";
			phandle = <0xb1>;
		};

		serial@2820000 {
			compatible = "ti,am64-uart\0ti,am654-uart";
			reg = <0x00 0x2820000 0x00 0x100>;
			interrupts = <0x00 0xb4 0x04>;
			power-domains = <0x09 0x99 0x01>;
			clocks = <0x07 0x99 0x00>;
			clock-names = "fclk";
			status = "disabled";
			phandle = <0xb2>;
		};

		serial@2830000 {
			compatible = "ti,am64-uart\0ti,am654-uart";
			reg = <0x00 0x2830000 0x00 0x100>;
			interrupts = <0x00 0xb5 0x04>;
			power-domains = <0x09 0x9a 0x01>;
			clocks = <0x07 0x9a 0x00>;
			clock-names = "fclk";
			status = "disabled";
			phandle = <0xb3>;
		};

		serial@2840000 {
			compatible = "ti,am64-uart\0ti,am654-uart";
			reg = <0x00 0x2840000 0x00 0x100>;
			interrupts = <0x00 0xb6 0x04>;
			power-domains = <0x09 0x9b 0x01>;
			clocks = <0x07 0x9b 0x00>;
			clock-names = "fclk";
			status = "disabled";
			phandle = <0xb4>;
		};

		serial@2850000 {
			compatible = "ti,am64-uart\0ti,am654-uart";
			reg = <0x00 0x2850000 0x00 0x100>;
			interrupts = <0x00 0xb7 0x04>;
			power-domains = <0x09 0x9c 0x01>;
			clocks = <0x07 0x9c 0x00>;
			clock-names = "fclk";
			status = "reserved";
			pinctrl-names = "default";
			pinctrl-0 = <0x2a>;
			phandle = <0xb5>;
		};

		serial@2860000 {
			compatible = "ti,am64-uart\0ti,am654-uart";
			reg = <0x00 0x2860000 0x00 0x100>;
			interrupts = <0x00 0xb8 0x04>;
			power-domains = <0x09 0x9e 0x01>;
			clocks = <0x07 0x9e 0x00>;
			clock-names = "fclk";
			status = "disabled";
			phandle = <0xb6>;
		};

		i2c@20000000 {
			compatible = "ti,am64-i2c\0ti,omap4-i2c";
			reg = <0x00 0x20000000 0x00 0x100>;
			interrupts = <0x00 0xa1 0x04>;
			#address-cells = <0x01>;
			#size-cells = <0x00>;
			power-domains = <0x09 0x66 0x01>;
			clocks = <0x07 0x66 0x02>;
			clock-names = "fck";
			status = "okay";
			pinctrl-names = "default";
			pinctrl-0 = <0x2b>;
			clock-frequency = <0x61a80>;
			bootph-all;
			phandle = <0xb7>;

			gpio@23 {
				compatible = "ti,tca6424";
				reg = <0x23>;
				gpio-controller;
				#gpio-cells = <0x02>;
				gpio-line-names = "TRC_MUX_SEL\0OSPI/ONAND_MUX_SEL\0MCASP1_FET_SEL\0CTRL_PM_I2C_OE#\0CSI_VIO_SEL\0USB2.0_MUX_SEL\0CSI01_MUX_SEL_2\0CSI23_MUX_SEL_2\0LMK1_OE1\0LMK1_OE0\0LMK2_OE0\0LMK2_OE1\0GPIO_RGMII1_RST#\0GPIO_AUD_RSTn\0GPIO_eMMC_RSTn\0GPIO_uSD_PWR_EN\0USER_LED2\0MCAN0_STB\0PCIe0_1L_RC_RSTz\0PCIe0_1L_PRSNT#\0ENET1_EXP_SPARE2\0ENET1_EXP_PWRDN\0PD_I2ENET1_I2CMUX_SELC_IRQ\0ENET1_EXP_RESETZ";
				bootph-all;
				phandle = <0x58>;

				p05-hog {
					gpio-hog;
					gpios = <0x05 0x01>;
					output-high;
				};

				p01-hog {
					gpio-hog;
					gpios = <0x00 0x00>;
					output-low;
					line-name = "TRC_MUX_SEL";
					phandle = <0xb8>;
				};

				p02-hog {
					gpio-hog;
					gpios = <0x02 0x00>;
					output-high;
					line-name = "MCASP1_FET_SEL";
					phandle = <0xb9>;
				};

				p13-hog {
					gpio-hog;
					gpios = <0x0d 0x00>;
					output-high;
					line-name = "GPIO_AUD_RSTn";
					phandle = <0xba>;
				};
			};

			audio-codec@1b {
				#sound-dai-cells = <0x00>;
				compatible = "ti,tlv320aic3106";
				reg = <0x1b>;
				ai3x-micbias-vg = <0x01>;
				AVDD-supply = <0x1c>;
				IOVDD-supply = <0x1c>;
				DRVDD-supply = <0x1c>;
				DVDD-supply = <0x2c>;
				phandle = <0x70>;
			};
		};

		i2c@20010000 {
			compatible = "ti,am64-i2c\0ti,omap4-i2c";
			reg = <0x00 0x20010000 0x00 0x100>;
			interrupts = <0x00 0xa2 0x04>;
			#address-cells = <0x01>;
			#size-cells = <0x00>;
			power-domains = <0x09 0x67 0x01>;
			clocks = <0x07 0x67 0x02>;
			clock-names = "fck";
			status = "okay";
			pinctrl-names = "default";
			pinctrl-0 = <0x2d>;
			clock-frequency = <0x186a0>;
			phandle = <0xbb>;

			gpio@20 {
				compatible = "ti,tca6416";
				reg = <0x20>;
				gpio-controller;
				#gpio-cells = <0x02>;
				gpio-line-names = "DSI_Mux_SEL_2\0GPIO_eDP_ENABLE\0DP0_PWR_SW_EN\0GPIO_OLDI_RSTn\0GPIO_HDMI_RSTn\0HDMI_LS_OE\0\0\0DSI_GPIO0\0DSI_GPIO1\0DSI_EDID\0IO_eDP_IRQ\0OLDI_INT#\0HDMI_INTn\0\0";
				interrupt-parent = <0x1b>;
				interrupts = <0x43 0x02>;
				interrupt-controller;
				#interrupt-cells = <0x02>;
				pinctrl-names = "default";
				pinctrl-0 = <0x2e>;
				bootph-all;
				phandle = <0x2f>;

				p04-hog {
					gpio-hog;
					gpios = <0x04 0x01>;
					output-low;
					line-name = "GPIO_HDMI_RSTn";
				};

				p03-hog {
					gpio-hog;
					gpios = <0x03 0x01>;
					output-low;
					line-name = "GPIO_OLDI_RSTn";
				};

				p05-hog {
					gpio-hog;
					gpios = <0x05 0x00>;
					output-high;
					line-name = "HDMI_LS_OE";
				};
			};

			bridge-hdmi@3b {
				compatible = "sil,sii9022";
				reg = <0x3b>;
				interrupt-parent = <0x2f>;
				interrupts = <0x0d 0x02>;
				#sound-dai-cells = <0x00>;
				sil,i2s-data-lanes = <0x00>;
				phandle = <0xbc>;

				ports {
					#address-cells = <0x01>;
					#size-cells = <0x00>;
					phandle = <0xbd>;

					port@0 {
						reg = <0x00>;

						endpoint {
							remote-endpoint = <0x30>;
							phandle = <0x4b>;
						};
					};

					port@1 {
						reg = <0x01>;

						endpoint {
							remote-endpoint = <0x31>;
							phandle = <0x74>;
						};
					};
				};
			};

			dsi-edp-bridge@2c {
				compatible = "ti,sn65dsi86";
				reg = <0x2c>;
				clock-names = "refclk";
				clocks = <0x32>;
				enable-gpios = <0x2f 0x01 0x00>;
				vpll-supply = <0x2c>;
				vccio-supply = <0x2c>;
				vcca-supply = <0x33>;
				vcc-supply = <0x33>;
				phandle = <0xbe>;

				ports {
					#address-cells = <0x01>;
					#size-cells = <0x00>;
					phandle = <0xbf>;

					port@0 {
						reg = <0x00>;

						endpoint {
							remote-endpoint = <0x34>;
							phandle = <0x4e>;
						};
					};

					port@1 {
						reg = <0x01>;

						endpoint {
							remote-endpoint = <0x35>;
							phandle = <0x76>;
						};
					};
				};
			};
		};

		i2c@20020000 {
			compatible = "ti,am64-i2c\0ti,omap4-i2c";
			reg = <0x00 0x20020000 0x00 0x100>;
			interrupts = <0x00 0xa3 0x04>;
			#address-cells = <0x01>;
			#size-cells = <0x00>;
			power-domains = <0x09 0x68 0x01>;
			clocks = <0x07 0x68 0x02>;
			clock-names = "fck";
			status = "okay";
			pinctrl-names = "default";
			pinctrl-0 = <0x36>;
			clock-frequency = <0x61a80>;
			phandle = <0xc0>;

			i2c-mux@70 {
				compatible = "nxp,pca9543";
				#address-cells = <0x01>;
				#size-cells = <0x00>;
				reg = <0x70>;
				phandle = <0xc1>;
			};

			i2c-mux@71 {
				compatible = "nxp,pca9543";
				#address-cells = <0x01>;
				#size-cells = <0x00>;
				reg = <0x71>;
				phandle = <0xc2>;
			};
		};

		i2c@20030000 {
			compatible = "ti,am64-i2c\0ti,omap4-i2c";
			reg = <0x00 0x20030000 0x00 0x100>;
			interrupts = <0x00 0xa4 0x04>;
			#address-cells = <0x01>;
			#size-cells = <0x00>;
			power-domains = <0x09 0x69 0x01>;
			clocks = <0x07 0x69 0x02>;
			clock-names = "fck";
			status = "disabled";
			phandle = <0xc3>;
		};

		spi@20100000 {
			compatible = "ti,am654-mcspi\0ti,omap4-mcspi";
			reg = <0x00 0x20100000 0x00 0x400>;
			interrupts = <0x00 0xac 0x04>;
			#address-cells = <0x01>;
			#size-cells = <0x00>;
			power-domains = <0x09 0x8d 0x01>;
			clocks = <0x07 0x8d 0x00>;
			status = "disabled";
			phandle = <0xc4>;
		};

		spi@20110000 {
			compatible = "ti,am654-mcspi\0ti,omap4-mcspi";
			reg = <0x00 0x20110000 0x00 0x400>;
			interrupts = <0x00 0xad 0x04>;
			#address-cells = <0x01>;
			#size-cells = <0x00>;
			power-domains = <0x09 0x8e 0x01>;
			clocks = <0x07 0x8e 0x00>;
			status = "disabled";
			phandle = <0xc5>;
		};

		spi@20120000 {
			compatible = "ti,am654-mcspi\0ti,omap4-mcspi";
			reg = <0x00 0x20120000 0x00 0x400>;
			interrupts = <0x00 0xae 0x04>;
			#address-cells = <0x01>;
			#size-cells = <0x00>;
			power-domains = <0x09 0x8f 0x01>;
			clocks = <0x07 0x8f 0x00>;
			status = "disabled";
			phandle = <0xc6>;
		};

		interrupt-controller@a00000 {
			compatible = "ti,sci-intr";
			reg = <0x00 0xa00000 0x00 0x800>;
			ti,intr-trigger-type = <0x01>;
			interrupt-controller;
			interrupt-parent = <0x01>;
			#interrupt-cells = <0x01>;
			ti,sci = <0x0b>;
			ti,sci-dev-id = <0x03>;
			ti,interrupt-ranges = <0x00 0x20 0x10>;
			phandle = <0x37>;
		};

		gpio@600000 {
			compatible = "ti,am64-gpio\0ti,keystone-gpio";
			reg = <0x00 0x600000 0x00 0x100>;
			gpio-controller;
			#gpio-cells = <0x02>;
			interrupt-parent = <0x37>;
			interrupts = <0xbe 0xbf 0xc0 0xc1 0xc2 0xc3>;
			interrupt-controller;
			#interrupt-cells = <0x02>;
			ti,davinci-gpio-unbanked = <0x00>;
			power-domains = <0x09 0x4d 0x01>;
			clocks = <0x07 0x4d 0x00>;
			clock-names = "gpio";
			gpio-ranges = <0x38 0x00 0x00 0x20 0x38 0x20 0x21 0x26 0x38 0x46 0x48 0x11>;
			ti,ngpio = <0x57>;
			phandle = <0x1b>;
		};

		gpio@601000 {
			compatible = "ti,am64-gpio\0ti,keystone-gpio";
			reg = <0x00 0x601000 0x00 0x100>;
			gpio-controller;
			#gpio-cells = <0x02>;
			interrupt-parent = <0x37>;
			interrupts = <0xb4 0xb5 0xb6 0xb7 0xb8 0xb9>;
			interrupt-controller;
			#interrupt-cells = <0x02>;
			ti,davinci-gpio-unbanked = <0x00>;
			power-domains = <0x09 0x4e 0x01>;
			clocks = <0x07 0x4e 0x00>;
			clock-names = "gpio";
			gpio-ranges = <0x38 0x07 0x65 0x19 0x38 0x2a 0x89 0x05 0x38 0x2f 0x8f 0x03 0x38 0x32 0x95 0x02>;
			gpio-reserved-ranges = <0x00 0x07 0x20 0x0a>;
			ti,ngpio = <0x49>;
			status = "okay";
			phandle = <0xc7>;
		};

		mmc@fa10000 {
			compatible = "ti,am64-sdhci-8bit";
			reg = <0x00 0xfa10000 0x00 0x1000 0x00 0xfa18000 0x00 0x400>;
			interrupts = <0x00 0x85 0x04>;
			power-domains = <0x09 0x39 0x01>;
			clocks = <0x07 0x39 0x01 0x07 0x39 0x02>;
			clock-names = "clk_ahb\0clk_xin";
			bus-width = <0x08>;
			mmc-ddr-1_8v;
			mmc-hs200-1_8v;
			ti,clkbuf-sel = <0x07>;
			ti,trm-icp = <0x08>;
			ti,otap-del-sel-legacy = <0x01>;
			ti,otap-del-sel-mmc-hs = <0x01>;
			ti,otap-del-sel-ddr52 = <0x06>;
			ti,otap-del-sel-hs200 = <0x08>;
			ti,itap-del-sel-legacy = <0x10>;
			ti,itap-del-sel-mmc-hs = <0x0a>;
			ti,itap-del-sel-ddr52 = <0x03>;
			status = "okay";
			disable-wp;
			bootph-all;
			ti,driver-strength-ohm = <0x32>;
			phandle = <0xc8>;
		};

		mmc@fa00000 {
			compatible = "ti,am62-sdhci";
			reg = <0x00 0xfa00000 0x00 0x1000 0x00 0xfa08000 0x00 0x400>;
			interrupts = <0x00 0x53 0x04>;
			power-domains = <0x09 0x3a 0x01>;
			clocks = <0x07 0x3a 0x05 0x07 0x3a 0x06>;
			clock-names = "clk_ahb\0clk_xin";
			bus-width = <0x04>;
			ti,clkbuf-sel = <0x07>;
			ti,otap-del-sel-legacy = <0x00>;
			ti,otap-del-sel-sd-hs = <0x00>;
			ti,otap-del-sel-sdr12 = <0x0f>;
			ti,otap-del-sel-sdr25 = <0x0f>;
			ti,otap-del-sel-sdr50 = <0x0c>;
			ti,otap-del-sel-ddr50 = <0x09>;
			ti,otap-del-sel-sdr104 = <0x06>;
			ti,itap-del-sel-legacy = <0x00>;
			ti,itap-del-sel-sd-hs = <0x00>;
			ti,itap-del-sel-sdr12 = <0x00>;
			ti,itap-del-sel-sdr25 = <0x00>;
			status = "okay";
			vmmc-supply = <0x39>;
			vqmmc-supply = <0x3a>;
			pinctrl-names = "default";
			pinctrl-0 = <0x3b>;
			ti,driver-strength-ohm = <0x32>;
			disable-wp;
			bootph-all;
			phandle = <0xc9>;
		};

		mmc@fa20000 {
			compatible = "ti,am62-sdhci";
			reg = <0x00 0xfa20000 0x00 0x1000 0x00 0xfa28000 0x00 0x400>;
			interrupts = <0x00 0x52 0x04>;
			power-domains = <0x09 0xb8 0x01>;
			clocks = <0x07 0xb8 0x05 0x07 0xb8 0x06>;
			clock-names = "clk_ahb\0clk_xin";
			bus-width = <0x04>;
			ti,clkbuf-sel = <0x07>;
			ti,otap-del-sel-legacy = <0x00>;
			ti,otap-del-sel-sd-hs = <0x00>;
			ti,otap-del-sel-sdr12 = <0x0f>;
			ti,otap-del-sel-sdr25 = <0x0f>;
			ti,otap-del-sel-sdr50 = <0x0c>;
			ti,otap-del-sel-ddr50 = <0x09>;
			ti,otap-del-sel-sdr104 = <0x06>;
			ti,itap-del-sel-legacy = <0x00>;
			ti,itap-del-sel-sd-hs = <0x00>;
			ti,itap-del-sel-sdr12 = <0x00>;
			ti,itap-del-sel-sdr25 = <0x00>;
			status = "disabled";
			phandle = <0xca>;
		};

		usb@f900000 {
			compatible = "ti,am62-usb";
			reg = <0x00 0xf900000 0x00 0x800 0x00 0xf908000 0x00 0x400>;
			clocks = <0x07 0xa1 0x03>;
			clock-names = "ref";
			ti,syscon-phy-pll-refclk = <0x3c 0x00>;
			#address-cells = <0x02>;
			#size-cells = <0x02>;
			power-domains = <0x09 0xb2 0x01>;
			ranges;
			status = "okay";
			ti,vbus-divider;
			phandle = <0xcb>;

			usb@31000000 {
				compatible = "snps,dwc3";
				reg = <0x00 0x31000000 0x00 0x50000>;
				interrupts = <0x00 0xbc 0x04 0x00 0xbc 0x04>;
				interrupt-names = "host\0peripheral";
				maximum-speed = "high-speed";
				dr_mode = "otg";
				bootph-all;
				snps,usb2-gadget-lpm-disable;
				snps,usb2-lpm-disable;
				usb-role-switch;
				phandle = <0xcc>;
			};
		};

		bus@fc00000 {
			compatible = "simple-bus";
			reg = <0x00 0xfc00000 0x00 0x70000>;
			#address-cells = <0x02>;
			#size-cells = <0x02>;
			ranges;
			phandle = <0xcd>;

			spi@fc40000 {
				compatible = "ti,am654-ospi\0cdns,qspi-nor";
				reg = <0x00 0xfc40000 0x00 0x100 0x05 0x00 0x01 0x00>;
				interrupts = <0x00 0x8b 0x04>;
				cdns,fifo-depth = <0x100>;
				cdns,fifo-width = <0x04>;
				cdns,trigger-address = <0x00>;
				cdns,phase-detect-selector = <0x00>;
				clocks = <0x07 0x4b 0x07>;
				assigned-clocks = <0x07 0x4b 0x07>;
				assigned-clock-parents = <0x07 0x4b 0x08>;
				assigned-clock-rates = <0x9ef21aa>;
				power-domains = <0x09 0x4b 0x01>;
				#address-cells = <0x01>;
				#size-cells = <0x00>;
				status = "okay";
				pinctrl-names = "default";
				pinctrl-0 = <0x3d>;
				phandle = <0xce>;

				flash@0 {
					compatible = "jedec,spi-nor";
					reg = <0x00>;
					spi-tx-bus-width = <0x08>;
					spi-rx-bus-width = <0x08>;
					spi-max-frequency = <0x17d7840>;
					cdns,tshsl-ns = <0x3c>;
					cdns,tsd2d-ns = <0x3c>;
					cdns,tchsh-ns = <0x3c>;
					cdns,tslch-ns = <0x3c>;
					cdns,read-delay = <0x04>;
					cdns,phy-mode;
					bootph-all;

					partitions {
						compatible = "fixed-partitions";
						#address-cells = <0x01>;
						#size-cells = <0x01>;

						partition@0 {
							label = "ospi.tiboot3";
							reg = <0x00 0x80000>;
						};

						partition@80000 {
							label = "ospi.tispl";
							reg = <0x80000 0x200000>;
						};

						partition@280000 {
							label = "ospi.u-boot";
							reg = <0x280000 0x400000>;
						};

						partition@680000 {
							label = "ospi.env";
							reg = <0x680000 0x40000>;
						};

						partition@6c0000 {
							label = "ospi.env.backup";
							reg = <0x6c0000 0x40000>;
						};

						partition@800000 {
							label = "ospi.rootfs";
							reg = <0x800000 0x37c0000>;
						};

						partition@3fc0000 {
							bootph-all;
							label = "ospi.phypattern";
							reg = <0x3fc0000 0x40000>;
						};
					};
				};

				nand@0 {
					compatible = "spi-nand";
					reg = <0x00>;
					spi-tx-bus-width = <0x08>;
					spi-rx-bus-width = <0x08>;
					spi-max-frequency = <0x17d7840>;
					cdns,tshsl-ns = <0x3c>;
					cdns,tsd2d-ns = <0x3c>;
					cdns,tchsh-ns = <0x3c>;
					cdns,tslch-ns = <0x3c>;
					cdns,read-delay = <0x02>;
					#address-cells = <0x01>;
					#size-cells = <0x01>;
					bootph-all;
					cdns,phy-mode;
					phandle = <0xcf>;

					partitions {
						compatible = "fixed-partitions";
						#address-cells = <0x01>;
						#size-cells = <0x01>;

						partition@0 {
							label = "ospi_nand.tiboot3";
							reg = <0x00 0x80000>;
						};

						partition@80000 {
							label = "ospi_nand.tispl";
							reg = <0x80000 0x200000>;
						};

						partition@280000 {
							label = "ospi_nand.u-boot";
							reg = <0x280000 0x400000>;
						};

						partition@680000 {
							label = "ospi_nand.env";
							reg = <0x680000 0x40000>;
						};

						partition@6c0000 {
							label = "ospi_nand.env.backup";
							reg = <0x6c0000 0x40000>;
						};

						partition@2000000 {
							label = "ospi_nand.rootfs";
							reg = <0x2000000 0x5fc0000>;
						};

						partition@7fc0000 {
							bootph-all;
							label = "ospi_nand.phypattern";
							reg = <0x7fc0000 0x40000>;
						};
					};
				};
			};
		};

		ethernet@8000000 {
			compatible = "ti,am642-cpsw-nuss";
			#address-cells = <0x02>;
			#size-cells = <0x02>;
			reg = <0x00 0x8000000 0x00 0x200000>;
			reg-names = "cpsw_nuss";
			ranges = <0x00 0x00 0x00 0x8000000 0x00 0x200000>;
			clocks = <0x07 0x0d 0x00>;
			assigned-clocks = <0x07 0x0d 0x03>;
			assigned-clock-parents = <0x07 0x0d 0x0b>;
			clock-names = "fck";
			power-domains = <0x09 0x0d 0x01>;
			status = "okay";
			dmas = <0x22 0xc600 0x0f 0x22 0xc601 0x0f 0x22 0xc602 0x0f 0x22 0xc603 0x0f 0x22 0xc604 0x0f 0x22 0xc605 0x0f 0x22 0xc606 0x0f 0x22 0xc607 0x0f 0x22 0x4600 0x0f>;
			dma-names = "tx0\0tx1\0tx2\0tx3\0tx4\0tx5\0tx6\0tx7\0rx";
			pinctrl-names = "default";
			pinctrl-0 = <0x3e>;
			phandle = <0xd0>;

			ethernet-ports {
				#address-cells = <0x01>;
				#size-cells = <0x00>;

				port@1 {
					reg = <0x01>;
					ti,mac-only;
					label = "port1";
					phys = <0x3f 0x01>;
					mac-address = [00 00 00 00 00 00];
					ti,syscon-efuse = <0x40 0x00>;
					status = "okay";
					bootph-all;
					phy-mode = "rgmii-rxid";
					phy-handle = <0x41>;
					phandle = <0xd1>;
				};

				port@2 {
					reg = <0x02>;
					ti,mac-only;
					label = "port2";
					phys = <0x3f 0x02>;
					mac-address = [00 00 00 00 00 00];
					status = "disabled";
					phandle = <0xd2>;
				};
			};

			mdio@f00 {
				compatible = "ti,cpsw-mdio\0ti,davinci_mdio";
				reg = <0x00 0xf00 0x00 0x100>;
				#address-cells = <0x01>;
				#size-cells = <0x00>;
				clocks = <0x07 0x0d 0x00>;
				clock-names = "fck";
				bus_freq = <0xf4240>;
				status = "okay";
				bootph-all;
				pinctrl-names = "default";
				pinctrl-0 = <0x42>;
				phandle = <0xd3>;

				ethernet-phy@0 {
					reg = <0x00>;
					bootph-all;
					ti,rx-internal-delay = <0x07>;
					ti,fifo-depth = <0x01>;
					ti,min-output-impedance;
					phandle = <0x41>;
				};
			};

			cpts@3d000 {
				compatible = "ti,j721e-cpts";
				reg = <0x00 0x3d000 0x00 0x400>;
				clocks = <0x07 0x0d 0x03>;
				clock-names = "cpts";
				interrupts-extended = <0x01 0x00 0x66 0x04>;
				interrupt-names = "cpts";
				ti,cpts-ext-ts-inputs = <0x04>;
				ti,cpts-periodic-outputs = <0x02>;
				ti,pps = <0x02 0x01>;
			};
		};

		gpu@fd80000 {
			compatible = "ti,am62p-pvr\0img,pvr-bxs64";
			reg = <0x00 0xfd80000 0x00 0x80000>;
			interrupts = <0x00 0xf1 0x04>;
			power-domains = <0x09 0xed 0x01 0x09 0xf2 0x01>;
			assigned-clocks = <0x07 0xed 0x03>;
			assigned-clock-rates = <0x2faf0800>;
			power-domain-names = "firmware\0dust";
			clocks = <0x07 0xed 0x03>;
			clock-names = "core";
			phandle = <0xd4>;
		};

		spinlock@2a000000 {
			compatible = "ti,am64-hwspinlock";
			reg = <0x00 0x2a000000 0x00 0x1000>;
			#hwlock-cells = <0x01>;
			phandle = <0xd5>;
		};

		mux-controller@a40000 {
			compatible = "reg-mux";
			reg = <0x00 0xa40000 0x00 0x800>;
			#mux-control-cells = <0x01>;
			status = "okay";
			mux-reg-masks-state = <0x34 0x1ffff 0x10011>;
			phandle = <0xd6>;
		};

		mailbox@29000000 {
			compatible = "ti,am64-mailbox";
			reg = <0x00 0x29000000 0x00 0x200>;
			interrupts = <0x00 0x4c 0x04>;
			#mbox-cells = <0x01>;
			ti,mbox-num-users = <0x04>;
			ti,mbox-num-fifos = <0x10>;
			status = "okay";
			phandle = <0x1d>;

			mbox-wkup-r5-0 {
				ti,mbox-rx = <0x00 0x00 0x00>;
				ti,mbox-tx = <0x01 0x00 0x00>;
				phandle = <0x1e>;
			};
		};

		mailbox@29010000 {
			compatible = "ti,am64-mailbox";
			reg = <0x00 0x29010000 0x00 0x200>;
			interrupts = <0x00 0x4d 0x04>;
			#mbox-cells = <0x01>;
			ti,mbox-num-users = <0x04>;
			ti,mbox-num-fifos = <0x10>;
			status = "okay";
			phandle = <0x14>;

			mbox-mcu-r5-0 {
				ti,mbox-rx = <0x00 0x00 0x00>;
				ti,mbox-tx = <0x01 0x00 0x00>;
				phandle = <0x15>;
			};
		};

		mailbox@29020000 {
			compatible = "ti,am64-mailbox";
			reg = <0x00 0x29020000 0x00 0x200>;
			interrupts = <0x00 0x6c 0x04>;
			#mbox-cells = <0x01>;
			ti,mbox-num-users = <0x04>;
			ti,mbox-num-fifos = <0x10>;
			status = "okay";
			phandle = <0x63>;

			mbox-c7x-0 {
				ti,mbox-rx = <0x00 0x00 0x00>;
				ti,mbox-tx = <0x01 0x00 0x00>;
				phandle = <0x64>;
			};
		};

		mailbox@29030000 {
			compatible = "ti,am64-mailbox";
			reg = <0x00 0x29030000 0x00 0x200>;
			interrupts = <0x00 0x6d 0x04>;
			#mbox-cells = <0x01>;
			ti,mbox-num-users = <0x04>;
			ti,mbox-num-fifos = <0x10>;
			status = "okay";
			phandle = <0x5f>;

			mbox-main-r5-0 {
				ti,mbox-rx = <0x00 0x00 0x00>;
				ti,mbox-tx = <0x01 0x00 0x00>;
				phandle = <0x60>;
			};

			mbox-c7x-1 {
				ti,mbox-rx = <0x02 0x00 0x00>;
				ti,mbox-tx = <0x03 0x00 0x00>;
				phandle = <0x67>;
			};
		};

		pwm@23100000 {
			compatible = "ti,am3352-ecap";
			#pwm-cells = <0x03>;
			reg = <0x00 0x23100000 0x00 0x100>;
			power-domains = <0x09 0x33 0x01>;
			clocks = <0x07 0x33 0x00>;
			clock-names = "fck";
			status = "disabled";
			phandle = <0xd7>;
		};

		pwm@23110000 {
			compatible = "ti,am3352-ecap";
			#pwm-cells = <0x03>;
			reg = <0x00 0x23110000 0x00 0x100>;
			power-domains = <0x09 0x34 0x01>;
			clocks = <0x07 0x34 0x00>;
			clock-names = "fck";
			status = "disabled";
			phandle = <0xd8>;
		};

		pwm@23120000 {
			compatible = "ti,am3352-ecap";
			#pwm-cells = <0x03>;
			reg = <0x00 0x23120000 0x00 0x100>;
			power-domains = <0x09 0x35 0x01>;
			clocks = <0x07 0x35 0x00>;
			clock-names = "fck";
			status = "disabled";
			phandle = <0xd9>;
		};

		counter@23200000 {
			compatible = "ti,am62-eqep";
			reg = <0x00 0x23200000 0x00 0x100>;
			power-domains = <0x09 0x3b 0x01>;
			clocks = <0x07 0x3b 0x00>;
			interrupts = <0x00 0x74 0x01>;
			status = "disabled";
			phandle = <0xda>;
		};

		counter@23210000 {
			compatible = "ti,am62-eqep";
			reg = <0x00 0x23210000 0x00 0x100>;
			power-domains = <0x09 0x3c 0x01>;
			clocks = <0x07 0x3c 0x00>;
			interrupts = <0x00 0x75 0x01>;
			status = "disabled";
			phandle = <0xdb>;
		};

		counter@23220000 {
			compatible = "ti,am62-eqep";
			reg = <0x00 0x23220000 0x00 0x100>;
			power-domains = <0x09 0x3e 0x01>;
			clocks = <0x07 0x3e 0x00>;
			interrupts = <0x00 0x76 0x01>;
			status = "disabled";
			phandle = <0xdc>;
		};

		can@20701000 {
			compatible = "bosch,m_can";
			reg = <0x00 0x20701000 0x00 0x200 0x00 0x20708000 0x00 0x8000>;
			reg-names = "m_can\0message_ram";
			power-domains = <0x09 0x62 0x01>;
			clocks = <0x07 0x62 0x06 0x07 0x62 0x01>;
			clock-names = "hclk\0cclk";
			interrupts = <0x00 0x9b 0x04 0x00 0x9c 0x04>;
			interrupt-names = "int0\0int1";
			bosch,mram-cfg = <0x00 0x80 0x40 0x40 0x40 0x40 0x20 0x20>;
			status = "okay";
			pinctrl-names = "default";
			pinctrl-0 = <0x43>;
			phys = <0x44>;
			phandle = <0xdd>;
		};

		can@20711000 {
			compatible = "bosch,m_can";
			reg = <0x00 0x20711000 0x00 0x200 0x00 0x20718000 0x00 0x8000>;
			reg-names = "m_can\0message_ram";
			power-domains = <0x09 0x63 0x01>;
			clocks = <0x07 0x63 0x06 0x07 0x63 0x01>;
			clock-names = "hclk\0cclk";
			interrupts = <0x00 0xd5 0x04 0x00 0xd6 0x04>;
			interrupt-names = "int0\0int1";
			bosch,mram-cfg = <0x00 0x80 0x40 0x40 0x40 0x40 0x20 0x20>;
			status = "disabled";
			phandle = <0xde>;
		};

		watchdog@e000000 {
			compatible = "ti,j7-rti-wdt";
			reg = <0x00 0xe000000 0x00 0x100>;
			clocks = <0x07 0x7d 0x00>;
			power-domains = <0x09 0x7d 0x01>;
			assigned-clocks = <0x07 0x7d 0x00>;
			assigned-clock-parents = <0x07 0x7d 0x04>;
			phandle = <0xdf>;
		};

		watchdog@e010000 {
			compatible = "ti,j7-rti-wdt";
			reg = <0x00 0xe010000 0x00 0x100>;
			clocks = <0x07 0x7e 0x00>;
			power-domains = <0x09 0x7e 0x01>;
			assigned-clocks = <0x07 0x7e 0x00>;
			assigned-clock-parents = <0x07 0x7e 0x04>;
			phandle = <0xe0>;
		};

		watchdog@e020000 {
			compatible = "ti,j7-rti-wdt";
			reg = <0x00 0xe020000 0x00 0x100>;
			clocks = <0x07 0x7f 0x00>;
			power-domains = <0x09 0x7f 0x01>;
			assigned-clocks = <0x07 0x7f 0x00>;
			assigned-clock-parents = <0x07 0x7f 0x04>;
			phandle = <0xe1>;
		};

		watchdog@e030000 {
			compatible = "ti,j7-rti-wdt";
			reg = <0x00 0xe030000 0x00 0x100>;
			clocks = <0x07 0x80 0x00>;
			power-domains = <0x09 0x80 0x01>;
			assigned-clocks = <0x07 0x80 0x00>;
			assigned-clock-parents = <0x07 0x80 0x04>;
			phandle = <0xe2>;
		};

		watchdog@e0f0000 {
			compatible = "ti,j7-rti-wdt";
			reg = <0x00 0xe0f0000 0x00 0x100>;
			clocks = <0x07 0x82 0x00>;
			power-domains = <0x09 0x82 0x01>;
			assigned-clocks = <0x07 0x82 0x00>;
			assigned-clock-parents = <0x07 0x82 0x02>;
			phandle = <0xe3>;
		};

		pwm@23000000 {
			compatible = "ti,am64-epwm\0ti,am3352-ehrpwm";
			#pwm-cells = <0x03>;
			reg = <0x00 0x23000000 0x00 0x100>;
			power-domains = <0x09 0x56 0x01>;
			clocks = <0x45 0x00 0x07 0x56 0x00>;
			clock-names = "tbclk\0fck";
			status = "disabled";
			phandle = <0xe4>;
		};

		pwm@23010000 {
			compatible = "ti,am64-epwm\0ti,am3352-ehrpwm";
			#pwm-cells = <0x03>;
			reg = <0x00 0x23010000 0x00 0x100>;
			power-domains = <0x09 0x57 0x01>;
			clocks = <0x45 0x01 0x07 0x57 0x00>;
			clock-names = "tbclk\0fck";
			status = "disabled";
			phandle = <0xe5>;
		};

		pwm@23020000 {
			compatible = "ti,am64-epwm\0ti,am3352-ehrpwm";
			#pwm-cells = <0x03>;
			reg = <0x00 0x23020000 0x00 0x100>;
			power-domains = <0x09 0x58 0x01>;
			clocks = <0x45 0x02 0x07 0x58 0x00>;
			clock-names = "tbclk\0fck";
			status = "disabled";
			phandle = <0xe6>;
		};

		audio-controller@2b00000 {
			compatible = "ti,am33xx-mcasp-audio";
			reg = <0x00 0x2b00000 0x00 0x2000 0x00 0x2b08000 0x00 0x400>;
			reg-names = "mpu\0dat";
			interrupts = <0x00 0xec 0x04 0x00 0xeb 0x04>;
			interrupt-names = "tx\0rx";
			dmas = <0x21 0x00 0xc500 0x00 0x21 0x00 0x4500 0x00>;
			dma-names = "tx\0rx";
			clocks = <0x07 0xbe 0x00>;
			clock-names = "fck";
			assigned-clocks = <0x07 0xbe 0x00>;
			assigned-clock-parents = <0x07 0xbe 0x02>;
			power-domains = <0x09 0xbe 0x01>;
			status = "disabled";
			phandle = <0xe7>;
		};

		audio-controller@2b10000 {
			compatible = "ti,am33xx-mcasp-audio";
			reg = <0x00 0x2b10000 0x00 0x2000 0x00 0x2b18000 0x00 0x400>;
			reg-names = "mpu\0dat";
			interrupts = <0x00 0xee 0x04 0x00 0xed 0x04>;
			interrupt-names = "tx\0rx";
			dmas = <0x21 0x00 0xc501 0x00 0x21 0x00 0x4501 0x00>;
			dma-names = "tx\0rx";
			clocks = <0x07 0xbf 0x00>;
			clock-names = "fck";
			assigned-clocks = <0x07 0xbf 0x00>;
			assigned-clock-parents = <0x07 0xbf 0x02>;
			power-domains = <0x09 0xbf 0x01>;
			status = "okay";
			#sound-dai-cells = <0x00>;
			pinctrl-names = "default";
			pinctrl-0 = <0x46>;
			op-mode = <0x00>;
			tdm-slots = <0x02>;
			serial-dir = <0x01 0x00 0x02 0x00 0x00 0x00 0x00 0x00 0x00 0x00 0x00 0x00 0x00 0x00 0x00 0x00>;
			phandle = <0x6f>;
		};

		audio-controller@2b20000 {
			compatible = "ti,am33xx-mcasp-audio";
			reg = <0x00 0x2b20000 0x00 0x2000 0x00 0x2b28000 0x00 0x400>;
			reg-names = "mpu\0dat";
			interrupts = <0x00 0xf0 0x04 0x00 0xef 0x04>;
			interrupt-names = "tx\0rx";
			dmas = <0x21 0x00 0xc502 0x00 0x21 0x00 0x4502 0x00>;
			dma-names = "tx\0rx";
			clocks = <0x07 0xc0 0x00>;
			clock-names = "fck";
			assigned-clocks = <0x07 0xc0 0x00>;
			assigned-clock-parents = <0x07 0xc0 0x02>;
			power-domains = <0x09 0xc0 0x01>;
			status = "disabled";
			phandle = <0xe8>;
		};

		ticsi2rx@30102000 {
			compatible = "ti,j721e-csi2rx-shim";
			reg = <0x00 0x30102000 0x00 0x1000>;
			ranges;
			#address-cells = <0x02>;
			#size-cells = <0x02>;
			dmas = <0x24 0x00 0x5000 0x00 0x24 0x00 0x5001 0x00 0x24 0x00 0x5002 0x00 0x24 0x00 0x5003 0x00 0x24 0x00 0x5004 0x00 0x24 0x00 0x5005 0x00>;
			dma-names = "rx0\0rx1\0rx2\0rx3\0rx4\0rx5";
			power-domains = <0x09 0xb6 0x01>;
			status = "disabled";
			phandle = <0xe9>;

			csi-bridge@30101000 {
				compatible = "ti,j721e-csi2rx\0cdns,csi2rx";
				reg = <0x00 0x30101000 0x00 0x1000>;
				interrupts = <0x00 0x8f 0x04 0x00 0x8d 0x04>;
				interrupt-names = "error_irq\0irq";
				clocks = <0x07 0xb6 0x00 0x07 0xb6 0x03 0x07 0xb6 0x00 0x07 0xb6 0x00 0x07 0xb6 0x04 0x07 0xb6 0x04>;
				clock-names = "sys_clk\0p_clk\0pixel_if0_clk\0pixel_if1_clk\0pixel_if2_clk\0pixel_if3_clk";
				phys = <0x47>;
				phy-names = "dphy";
				phandle = <0xea>;

				ports {
					#address-cells = <0x01>;
					#size-cells = <0x00>;

					port@0 {
						reg = <0x00>;
						status = "disabled";
						phandle = <0xeb>;
					};

					port@1 {
						reg = <0x01>;
						status = "disabled";
						phandle = <0xec>;
					};

					port@2 {
						reg = <0x02>;
						status = "disabled";
						phandle = <0xed>;
					};

					port@3 {
						reg = <0x03>;
						status = "disabled";
						phandle = <0xee>;
					};

					port@4 {
						reg = <0x04>;
						status = "disabled";
						phandle = <0xef>;
					};
				};
			};
		};

		phy@30110000 {
			compatible = "cdns,dphy-rx";
			reg = <0x00 0x30110000 0x00 0x1100>;
			#phy-cells = <0x00>;
			power-domains = <0x09 0xb9 0x01>;
			status = "disabled";
			phandle = <0x47>;
		};

		dss@30200000 {
			compatible = "ti,am62p51-dss";
			reg = <0x00 0x30200000 0x00 0x1000 0x00 0x30202000 0x00 0x1000 0x00 0x30206000 0x00 0x1000 0x00 0x30207000 0x00 0x1000 0x00 0x30208000 0x00 0x1000 0x00 0x3020a000 0x00 0x1000 0x00 0x3020b000 0x00 0x1000 0x00 0x30201000 0x00 0x1000>;
			reg-names = "common\0vidl1\0vid\0ovr1\0ovr2\0vp1\0vp2\0common1";
			power-domains = <0x09 0xba 0x01 0x09 0xf3 0x01 0x09 0xf4 0x01>;
			clocks = <0x07 0xba 0x06 0x48 0x07 0xba 0x02>;
			clock-names = "fck\0vp1\0vp2";
			interrupts = <0x00 0x54 0x04>;
			status = "disabled";
			phandle = <0xf0>;

			oldi-transmitters {
				#address-cells = <0x01>;
				#size-cells = <0x00>;

				oldi@0 {
					reg = <0x00>;
					clocks = <0x07 0xba 0x00>;
					clock-names = "serial";
					ti,oldi-io-ctrl = <0x49>;
					status = "disabled";
					phandle = <0xf1>;

					ports {
						phandle = <0xf2>;
					};
				};

				oldi@1 {
					reg = <0x01>;
					status = "disabled";
					phandle = <0xf3>;

					ports {
						phandle = <0xf4>;
					};
				};
			};

			ports {
				#address-cells = <0x01>;
				#size-cells = <0x00>;
				phandle = <0xf5>;
			};
		};

		dss@30220000 {
			compatible = "ti,am62p52-dss";
			reg = <0x00 0x30220000 0x00 0x1000 0x00 0x30222000 0x00 0x1000 0x00 0x30226000 0x00 0x1000 0x00 0x30227000 0x00 0x1000 0x00 0x30228000 0x00 0x1000 0x00 0x3022a000 0x00 0x1000 0x00 0x3022b000 0x00 0x1000 0x00 0x30221000 0x00 0x1000>;
			reg-names = "common\0vidl1\0vid\0ovr1\0ovr2\0vp1\0vp2\0common1";
			power-domains = <0x09 0xe8 0x01 0x09 0xf4 0x01>;
			clocks = <0x07 0xe8 0x08 0x07 0xe8 0x00 0x07 0xe8 0x04>;
			clock-names = "fck\0vp1\0vp2";
			interrupts = <0x00 0x1e 0x04>;
			status = "okay";
			pinctrl-names = "default";
			pinctrl-0 = <0x4a>;
			assigned-clocks = <0x07 0xf1 0x00 0x07 0xf0 0x00 0x07 0xf5 0x00>;
			assigned-clock-parents = <0x07 0xf1 0x02 0x07 0xf0 0x01 0x07 0xf5 0x02>;
			phandle = <0xf6>;

			oldi-transmitters {
				#address-cells = <0x01>;
				#size-cells = <0x00>;

				oldi@1 {
					reg = <0x00>;
					clocks = <0x07 0xe8 0x00>;
					clock-names = "serial";
					ti,oldi-io-ctrl = <0x49>;
					status = "disabled";
					phandle = <0xf7>;

					ports {
						phandle = <0xf8>;
					};
				};
			};

			ports {
				#address-cells = <0x01>;
				#size-cells = <0x00>;
				phandle = <0xf9>;

				port@0 {
					reg = <0x00>;

					endpoint {
						remote-endpoint = <0x4b>;
						phandle = <0x30>;
					};
				};

				port@1 {
					reg = <0x01>;

					endpoint {
						remote-endpoint = <0x4c>;
						phandle = <0x4f>;
					};
				};
			};
		};

		phy@301c0000 {
			compatible = "ti,j721e-dphy";
			reg = <0x00 0x301c0000 0x00 0x1000>;
			clocks = <0x07 0xee 0x10 0x07 0xee 0x01>;
			clock-names = "psm\0pll_ref";
			#phy-cells = <0x00>;
			power-domains = <0x09 0xee 0x01>;
			assigned-clocks = <0x07 0xee 0x01>;
			assigned-clock-parents = <0x07 0xee 0x02>;
			assigned-clock-rates = <0x17d7840>;
			status = "okay";
			phandle = <0x4d>;
		};

		dsi@30500000 {
			compatible = "ti,j721e-dsi";
			reg = <0x00 0x30500000 0x00 0x100000 0x00 0x30270000 0x00 0x100>;
			clocks = <0x07 0xe7 0x02 0x07 0xe7 0x05>;
			clock-names = "dsi_p_clk\0dsi_sys_clk";
			power-domains = <0x09 0xe7 0x01>;
			interrupt-parent = <0x01>;
			interrupts = <0x00 0x56 0x04>;
			phys = <0x4d>;
			phy-names = "dphy";
			status = "okay";
			phandle = <0xfa>;

			ports {
				#address-cells = <0x01>;
				#size-cells = <0x00>;

				port@0 {
					reg = <0x00>;

					endpoint {
						remote-endpoint = <0x4e>;
						phandle = <0x34>;
					};
				};

				port@1 {
					reg = <0x01>;

					endpoint {
						remote-endpoint = <0x4f>;
						phandle = <0x4c>;
					};
				};
			};
		};

		video-codec@30210000 {
			compatible = "ti,j721s2-wave521c\0cnm,wave521c";
			reg = <0x00 0x30210000 0x00 0x10000>;
			interrupts = <0x00 0xe1 0x04>;
			clocks = <0x07 0xcc 0x02>;
			power-domains = <0x09 0xcc 0x01>;
			sram = <0x50>;
			operating-points-v2 = <0x51>;
			phandle = <0xfb>;

			opp-table {
				compatible = "operating-points-v2";
				phandle = <0x51>;

				opp-20000000 {
					opp-hz = <0x00 0x1312d00>;
				};

				opp-100000000 {
					opp-hz = <0x00 0x5f5e100>;
				};

				opp-200000000 {
					opp-hz = <0x00 0xbebc200>;
				};

				opp-400000000 {
					opp-hz = <0x00 0x17d78400>;
				};

				opp-500000000 {
					opp-hz = <0x00 0x1dcd6500>;
				};
			};
		};

		phy@f000000 {
			compatible = "ti,am64-wiz-10g";
			ranges = <0xf000000 0x00 0xf000000 0x10000>;
			#address-cells = <0x01>;
			#size-cells = <0x01>;
			power-domains = <0x09 0x117 0x01>;
			clocks = <0x07 0x117 0x00 0x07 0x117 0x01 0x52>;
			clock-names = "fck\0core_ref_clk\0ext_ref_clk";
			num-lanes = <0x01>;
			#reset-cells = <0x01>;
			#clock-cells = <0x01>;
			assigned-clocks = <0x07 0x117 0x01>;
			assigned-clock-parents = <0x07 0x117 0x05>;
			status = "okay";
			phandle = <0x53>;

			serdes@f000000 {
				compatible = "ti,j721e-serdes-10g";
				reg = <0xf000000 0x10000>;
				reg-names = "torrent_phy";
				resets = <0x53 0x00>;
				reset-names = "torrent_reset";
				clocks = <0x53 0x00 0x53 0x10>;
				clock-names = "refclk\0phy_en_refclk";
				assigned-clocks = <0x53 0x00 0x53 0x01 0x53 0x02>;
				assigned-clock-parents = <0x07 0x117 0x01 0x07 0x117 0x01 0x07 0x117 0x01>;
				#address-cells = <0x01>;
				#size-cells = <0x00>;
				#clock-cells = <0x01>;
				status = "okay";
				phandle = <0xfc>;

				phy@0 {
					reg = <0x00>;
					cdns,num-lanes = <0x01>;
					#phy-cells = <0x00>;
					cdns,phy-type = <0x04>;
					resets = <0x53 0x01>;
					phandle = <0x5b>;
				};
			};
		};

		phy@f010000 {
			compatible = "ti,am64-wiz-10g";
			ranges = <0xf010000 0x00 0xf010000 0x10000>;
			#address-cells = <0x01>;
			#size-cells = <0x01>;
			power-domains = <0x09 0x118 0x01>;
			clocks = <0x07 0x118 0x00 0x07 0x118 0x01 0x52>;
			clock-names = "fck\0core_ref_clk\0ext_ref_clk";
			num-lanes = <0x01>;
			#reset-cells = <0x01>;
			#clock-cells = <0x01>;
			assigned-clocks = <0x07 0x118 0x01>;
			assigned-clock-parents = <0x07 0x118 0x05>;
			status = "okay";
			phandle = <0x54>;

			serdes@f010000 {
				compatible = "ti,j721e-serdes-10g";
				reg = <0xf010000 0x10000>;
				reg-names = "torrent_phy";
				resets = <0x54 0x00>;
				reset-names = "torrent_reset";
				clocks = <0x54 0x00 0x54 0x10>;
				clock-names = "refclk\0phy_en_refclk";
				assigned-clocks = <0x54 0x00 0x54 0x01 0x54 0x02>;
				assigned-clock-parents = <0x07 0x118 0x01 0x07 0x118 0x01 0x07 0x118 0x01>;
				#address-cells = <0x01>;
				#size-cells = <0x00>;
				#clock-cells = <0x01>;
				status = "okay";
				phandle = <0x55>;

				phy@0 {
					reg = <0x00>;
					cdns,num-lanes = <0x01>;
					#phy-cells = <0x00>;
					cdns,phy-type = <0x02>;
					resets = <0x54 0x01>;
					phandle = <0x59>;
				};
			};
		};

		pcie@f102000 {
			compatible = "ti,j722s-pcie-host\0ti,j721e-pcie-host";
			reg = <0x00 0xf102000 0x00 0x1000 0x00 0xf100000 0x00 0x400 0x00 0xd000000 0x00 0x800000 0x06 0x00 0x00 0x1000>;
			reg-names = "intd_cfg\0user_cfg\0reg\0cfg";
			ranges = <0x1000000 0x00 0x1000 0x06 0x1000 0x00 0x100000 0x2000000 0x00 0x101000 0x06 0x101000 0x00 0xffeff000>;
			dma-ranges = <0x2000000 0x00 0x00 0x00 0x00 0x10000 0x00>;
			interrupt-names = "link_state";
			interrupts = <0x00 0x63 0x01>;
			device_type = "pci";
			max-link-speed = <0x03>;
			num-lanes = <0x01>;
			power-domains = <0x09 0x103 0x01>;
			clocks = <0x07 0x103 0x00 0x55 0x00>;
			clock-names = "fck\0pcie_refclk";
			#address-cells = <0x03>;
			#size-cells = <0x02>;
			bus-range = <0x00 0xff>;
			vendor-id = <0x104c>;
			device-id = <0xb010>;
			cdns,no-bar-match-nbits = <0x40>;
			ti,syscon-pcie-ctrl = <0x56 0x00>;
			msi-map = <0x00 0x57 0x00 0x10000>;
			status = "okay";
			reset-gpios = <0x58 0x12 0x00>;
			phys = <0x59>;
			phy-names = "pcie-phy";
			phandle = <0xfd>;
		};

		usb@f920000 {
			compatible = "ti,j721e-usb";
			reg = <0x00 0xf920000 0x00 0x100>;
			power-domains = <0x09 0x116 0x01>;
			clocks = <0x07 0x116 0x03 0x07 0x116 0x01>;
			clock-names = "ref\0lpm";
			assigned-clocks = <0x07 0x116 0x03>;
			assigned-clock-parents = <0x07 0x116 0x04>;
			#address-cells = <0x02>;
			#size-cells = <0x02>;
			ranges;
			status = "okay";
			pinctrl-names = "default";
			pinctrl-0 = <0x5a>;
			ti,vbus-divider;
			phandle = <0xfe>;

			usb@31200000 {
				compatible = "cdns,usb3";
				reg = <0x00 0x31200000 0x00 0x10000 0x00 0x31210000 0x00 0x10000 0x00 0x31220000 0x00 0x10000>;
				reg-names = "otg\0xhci\0dev";
				interrupts = <0x00 0xe2 0x04 0x00 0xe8 0x04 0x00 0xf5 0x04>;
				interrupt-names = "host\0peripheral\0otg";
				maximum-speed = "super-speed";
				dr_mode = "host";
				phys = <0x5b>;
				phy-names = "cdns3,usb3-phy";
				phandle = <0xff>;
			};
		};

		ticsi2rx@30122000 {
			compatible = "ti,j721e-csi2rx-shim";
			reg = <0x00 0x30122000 0x00 0x1000>;
			ranges;
			#address-cells = <0x02>;
			#size-cells = <0x02>;
			dmas = <0x24 0x00 0x5100 0x00 0x24 0x00 0x5101 0x00 0x24 0x00 0x5102 0x00 0x24 0x00 0x5103 0x00>;
			dma-names = "rx0\0rx1\0rx2\0rx3";
			power-domains = <0x09 0xf7 0x01>;
			status = "disabled";
			phandle = <0x100>;

			csi-bridge@30121000 {
				compatible = "ti,j721e-csi2rx\0cdns,csi2rx";
				reg = <0x00 0x30121000 0x00 0x1000>;
				interrupts = <0x00 0x92 0x04 0x00 0x93 0x04>;
				interrupt-names = "error_irq\0irq";
				clocks = <0x07 0xf7 0x00 0x07 0xf7 0x03 0x07 0xf7 0x00 0x07 0xf7 0x00 0x07 0xf7 0x04 0x07 0xf7 0x04>;
				clock-names = "sys_clk\0p_clk\0pixel_if0_clk\0pixel_if1_clk\0pixel_if2_clk\0pixel_if3_clk";
				phys = <0x5c>;
				phy-names = "dphy";
				phandle = <0x101>;

				ports {
					#address-cells = <0x01>;
					#size-cells = <0x00>;

					port@0 {
						reg = <0x00>;
						status = "disabled";
						phandle = <0x102>;
					};

					port@1 {
						reg = <0x01>;
						status = "disabled";
						phandle = <0x103>;
					};

					port@2 {
						reg = <0x02>;
						status = "disabled";
						phandle = <0x104>;
					};

					port@3 {
						reg = <0x03>;
						status = "disabled";
						phandle = <0x105>;
					};

					port@4 {
						reg = <0x04>;
						status = "disabled";
						phandle = <0x106>;
					};
				};
			};
		};

		ticsi2rx@30142000 {
			compatible = "ti,j721e-csi2rx-shim";
			reg = <0x00 0x30142000 0x00 0x1000>;
			ranges;
			#address-cells = <0x02>;
			#size-cells = <0x02>;
			power-domains = <0x09 0xf8 0x01>;
			dmas = <0x24 0x00 0x5200 0x00 0x24 0x00 0x5201 0x00 0x24 0x00 0x5202 0x00 0x24 0x00 0x5203 0x00>;
			dma-names = "rx0\0rx1\0rx2\0rx3";
			status = "disabled";
			phandle = <0x107>;

			csi-bridge@30141000 {
				compatible = "ti,j721e-csi2rx\0cdns,csi2rx";
				reg = <0x00 0x30141000 0x00 0x1000>;
				interrupts = <0x00 0xbb 0x04 0x00 0xc8 0x04>;
				interrupt-names = "error_irq\0irq";
				clocks = <0x07 0xf8 0x00 0x07 0xf8 0x03 0x07 0xf8 0x00 0x07 0xf8 0x00 0x07 0xf8 0x04 0x07 0xf8 0x04>;
				clock-names = "sys_clk\0p_clk\0pixel_if0_clk\0pixel_if1_clk\0pixel_if2_clk\0pixel_if3_clk";
				phys = <0x5d>;
				phy-names = "dphy";
				phandle = <0x108>;

				ports {
					#address-cells = <0x01>;
					#size-cells = <0x00>;

					port@0 {
						reg = <0x00>;
						status = "disabled";
						phandle = <0x109>;
					};

					port@1 {
						reg = <0x01>;
						status = "disabled";
						phandle = <0x10a>;
					};

					port@2 {
						reg = <0x02>;
						status = "disabled";
						phandle = <0x10b>;
					};

					port@3 {
						reg = <0x03>;
						status = "disabled";
						phandle = <0x10c>;
					};

					port@4 {
						reg = <0x04>;
						status = "disabled";
						phandle = <0x10d>;
					};
				};
			};
		};

		ticsi2rx@30162000 {
			compatible = "ti,j721e-csi2rx-shim";
			reg = <0x00 0x30162000 0x00 0x1000>;
			ranges;
			#address-cells = <0x02>;
			#size-cells = <0x02>;
			dmas = <0x24 0x00 0x5300 0x00 0x24 0x00 0x5301 0x00 0x24 0x00 0x5302 0x00 0x24 0x00 0x5303 0x00>;
			dma-names = "rx0\0rx1\0rx2\0rx3";
			power-domains = <0x09 0xf9 0x01>;
			status = "disabled";
			phandle = <0x10e>;

			csi-bridge@30161000 {
				compatible = "ti,j721e-csi2rx\0cdns,csi2rx";
				reg = <0x00 0x30161000 0x00 0x1000>;
				interrupts = <0x00 0xd9 0x04 0x00 0xda 0x04>;
				interrupt-names = "error_irq\0irq";
				clocks = <0x07 0xf9 0x00 0x07 0xf9 0x03 0x07 0xf9 0x00 0x07 0xf9 0x00 0x07 0xf9 0x04 0x07 0xf9 0x04>;
				clock-names = "sys_clk\0p_clk\0pixel_if0_clk\0pixel_if1_clk\0pixel_if2_clk\0pixel_if3_clk";
				phys = <0x5e>;
				phy-names = "dphy";
				phandle = <0x10f>;

				ports {
					#address-cells = <0x01>;
					#size-cells = <0x00>;

					port@0 {
						reg = <0x00>;
						status = "disabled";
						phandle = <0x110>;
					};

					port@1 {
						reg = <0x01>;
						status = "disabled";
						phandle = <0x111>;
					};

					port@2 {
						reg = <0x02>;
						status = "disabled";
						phandle = <0x112>;
					};

					port@3 {
						reg = <0x03>;
						status = "disabled";
						phandle = <0x113>;
					};

					port@4 {
						reg = <0x04>;
						status = "disabled";
						phandle = <0x114>;
					};
				};
			};
		};

		phy@30130000 {
			compatible = "cdns,dphy-rx";
			reg = <0x00 0x30130000 0x00 0x1100>;
			#phy-cells = <0x00>;
			power-domains = <0x09 0xfb 0x01>;
			status = "disabled";
			phandle = <0x5c>;
		};

		phy@30150000 {
			compatible = "cdns,dphy-rx";
			reg = <0x00 0x30150000 0x00 0x1100>;
			#phy-cells = <0x00>;
			power-domains = <0x09 0xfc 0x01>;
			status = "disabled";
			phandle = <0x5d>;
		};

		phy@30170000 {
			compatible = "cdns,dphy-rx";
			reg = <0x00 0x30170000 0x00 0x1100>;
			#phy-cells = <0x00>;
			power-domains = <0x09 0xfd 0x01>;
			status = "disabled";
			phandle = <0x5e>;
		};

		r5fss@78400000 {
			compatible = "ti,am62-r5fss";
			#address-cells = <0x01>;
			#size-cells = <0x01>;
			ranges = <0x78400000 0x00 0x78400000 0x8000 0x78500000 0x00 0x78500000 0x8000>;
			power-domains = <0x09 0x105 0x01>;
			status = "okay";
			phandle = <0x115>;

			r5f@78400000 {
				compatible = "ti,am62-r5f";
				reg = <0x78400000 0x8000 0x78500000 0x8000>;
				reg-names = "atcm\0btcm";
				resets = <0x12 0x106 0x01>;
				firmware-name = "j722s-main-r5f0_0-fw";
				ti,sci = <0x0b>;
				ti,sci-dev-id = <0x106>;
				ti,sci-proc-ids = <0x04 0xff>;
				ti,atcm-enable = <0x01>;
				ti,btcm-enable = <0x01>;
				ti,loczrama = <0x01>;
				mboxes = <0x5f 0x60>;
				memory-region = <0x61 0x62>;
				phandle = <0x116>;
			};
		};

		dsp@7e000000 {
			compatible = "ti,j722s-c7xv-dsp";
			reg = <0x00 0x7e000000 0x00 0x200000>;
			reg-names = "l2sram";
			resets = <0x12 0xd0 0x01>;
			firmware-name = "j722s-c71_0-fw";
			ti,sci = <0x0b>;
			ti,sci-dev-id = <0xd0>;
			ti,sci-proc-ids = <0x30 0xff>;
			status = "okay";
			mboxes = <0x63 0x64>;
			memory-region = <0x65 0x66>;
			phandle = <0x117>;
		};

		dsp@7e200000 {
			compatible = "ti,j722s-c7xv-dsp";
			reg = <0x00 0x7e200000 0x00 0x200000>;
			reg-names = "l2sram";
			resets = <0x12 0x10c 0x01>;
			firmware-name = "j722s-c71_1-fw";
			ti,sci = <0x0b>;
			ti,sci-dev-id = <0x10c>;
			ti,sci-proc-ids = <0x31 0xff>;
			status = "okay";
			mboxes = <0x5f 0x67>;
			memory-region = <0x68 0x69>;
			phandle = <0x118>;
		};

		e5010@fd20000 {
			compatible = "img,e5010-jpeg-enc";
			reg = <0x00 0xfd20000 0x00 0x100 0x00 0xfd20200 0x00 0x200>;
			reg-names = "core\0mmu";
			clocks = <0x07 0xc9 0x00>;
			clock-names = "core_clk";
			power-domains = <0x09 0xc9 0x01>;
			interrupts = <0x00 0x62 0x04>;
			phandle = <0x119>;
		};
	};

	clock-divider-oldi-dss0 {
		compatible = "fixed-factor-clock";
		clocks = <0x07 0xba 0x00>;
		#clock-cells = <0x00>;
		clock-div = <0x07>;
		clock-mult = <0x01>;
		phandle = <0x48>;
	};

	clock-divider-oldi-dss1 {
		compatible = "fixed-factor-clock";
		clocks = <0x07 0xe8 0x00>;
		#clock-cells = <0x00>;
		clock-div = <0x07>;
		clock-mult = <0x01>;
		phandle = <0x11a>;
	};

	thermal-zones {
		phandle = <0x11b>;

		main0-thermal {
			polling-delay-passive = <0xfa>;
			polling-delay = <0x1f4>;
			thermal-sensors = <0x6a 0x00>;
			phandle = <0x11c>;

			trips {

				main0-crit {
					temperature = <0x1e848>;
					hysteresis = <0x7d0>;
					type = "critical";
					phandle = <0x11d>;
				};
			};
		};

		main1-thermal {
			polling-delay-passive = <0xfa>;
			polling-delay = <0x1f4>;
			thermal-sensors = <0x6a 0x01>;
			phandle = <0x11e>;

			trips {

				main1-crit {
					temperature = <0x1e848>;
					hysteresis = <0x7d0>;
					type = "critical";
					phandle = <0x11f>;
				};
			};
		};

		main2-thermal {
			polling-delay-passive = <0xfa>;
			polling-delay = <0x1f4>;
			thermal-sensors = <0x6a 0x02>;
			phandle = <0x120>;

			trips {

				main2-crit {
					temperature = <0x1e848>;
					hysteresis = <0x7d0>;
					type = "critical";
					phandle = <0x121>;
				};
			};
		};
	};

	clk-0 {
		compatible = "fixed-clock";
		#clock-cells = <0x00>;
		clock-frequency = <0x00>;
		phandle = <0x52>;
	};

	aliases {
		serial0 = "/bus@f0000/bus@b00000/target-module@2b300050/serial@0";
		serial2 = "/bus@f0000/serial@2800000";
		serial3 = "/bus@f0000/serial@2850000";
		mmc0 = "/bus@f0000/mmc@fa10000";
		mmc1 = "/bus@f0000/mmc@fa00000";
	};

	chosen {
		stdout-path = "/bus@f0000/serial@2800000";
	};

	memory@80000000 {
		reg = <0x00 0x80000000 0x00 0x80000000 0x08 0x80000000 0x01 0x80000000>;
		device_type = "memory";
		bootph-pre-ram;
	};

	reserved-memory {
		#address-cells = <0x02>;
		#size-cells = <0x02>;
		ranges;
		phandle = <0x122>;

		linux,cma {
			compatible = "shared-dma-pool";
			reusable;
			size = <0x00 0x38000000>;
			linux,cma-default;
		};

		tfa@9e780000 {
			reg = <0x00 0x9e780000 0x00 0x80000>;
			no-map;
			phandle = <0x123>;
		};

		optee@9e800000 {
			reg = <0x00 0x9e800000 0x00 0x1800000>;
			no-map;
			phandle = <0x124>;
		};

		r5f-dma-memory@a0000000 {
			compatible = "shared-dma-pool";
			reg = <0x00 0xa0000000 0x00 0x100000>;
			no-map;
			phandle = <0x1f>;
		};

		r5f-memory@a0100000 {
			compatible = "shared-dma-pool";
			reg = <0x00 0xa0100000 0x00 0xf00000>;
			no-map;
			phandle = <0x20>;
		};

		mcu-r5fss-dma-memory-region@a1000000 {
			compatible = "shared-dma-pool";
			reg = <0x00 0xa1000000 0x00 0x100000>;
			no-map;
			phandle = <0x16>;
		};

		mcu-r5fss-memory-region@a1100000 {
			compatible = "shared-dma-pool";
			reg = <0x00 0xa1100000 0x00 0xf00000>;
			no-map;
			phandle = <0x17>;
		};

		main-r5fss-dma-memory-region@a2000000 {
			compatible = "shared-dma-pool";
			reg = <0x00 0xa2000000 0x00 0x100000>;
			no-map;
			phandle = <0x61>;
		};

		main-r5fss-memory-region@a2100000 {
			compatible = "shared-dma-pool";
			reg = <0x00 0xa2100000 0x00 0xf00000>;
			no-map;
			phandle = <0x62>;
		};

		c7x-dma-memory@a3000000 {
			compatible = "shared-dma-pool";
			reg = <0x00 0xa3000000 0x00 0x100000>;
			no-map;
			phandle = <0x65>;
		};

		c7x-memory@a3100000 {
			compatible = "shared-dma-pool";
			reg = <0x00 0xa3100000 0x00 0xf00000>;
			no-map;
			phandle = <0x66>;
		};

		c7x-dma-memory@a4000000 {
			compatible = "shared-dma-pool";
			reg = <0x00 0xa4000000 0x00 0x100000>;
			no-map;
			phandle = <0x68>;
		};

		c7x-memory@a4100000 {
			compatible = "shared-dma-pool";
			reg = <0x00 0xa4100000 0x00 0xf00000>;
			no-map;
			phandle = <0x69>;
		};

		ipc-memories@a5000000 {
			reg = <0x00 0xa5000000 0x00 0x1c00000>;
			alignment = <0x1000>;
			no-map;
			phandle = <0x125>;
		};
	};

	regulator-0 {
		compatible = "regulator-fixed";
		regulator-name = "vmain_pd";
		regulator-min-microvolt = <0x4c4b40>;
		regulator-max-microvolt = <0x4c4b40>;
		regulator-always-on;
		regulator-boot-on;
		bootph-all;
		phandle = <0x6b>;
	};

	regulator-vsys5v0 {
		compatible = "regulator-fixed";
		regulator-name = "vsys_5v0";
		regulator-min-microvolt = <0x4c4b40>;
		regulator-max-microvolt = <0x4c4b40>;
		vin-supply = <0x6b>;
		regulator-always-on;
		regulator-boot-on;
		phandle = <0x6d>;
	};

	regulator-mmc1 {
		compatible = "regulator-fixed";
		regulator-name = "vdd_mmc1";
		regulator-min-microvolt = <0x325aa0>;
		regulator-max-microvolt = <0x325aa0>;
		regulator-boot-on;
		enable-active-high;
		gpio = <0x58 0x0f 0x00>;
		bootph-all;
		phandle = <0x39>;
	};

	regulator-TLV71033 {
		compatible = "regulator-gpio";
		regulator-name = "tlv71033";
		pinctrl-names = "default";
		pinctrl-0 = <0x6c>;
		regulator-min-microvolt = <0x1b7740>;
		regulator-max-microvolt = <0x325aa0>;
		regulator-boot-on;
		vin-supply = <0x6d>;
		gpios = <0x1b 0x46 0x00>;
		states = <0x1b7740 0x00 0x325aa0 0x01>;
		phandle = <0x3a>;
	};

	regulator-vsys-io-3v3 {
		compatible = "regulator-fixed";
		regulator-name = "vsys_io_3v3";
		regulator-min-microvolt = <0x325aa0>;
		regulator-max-microvolt = <0x325aa0>;
		regulator-always-on;
		regulator-boot-on;
		phandle = <0x1c>;
	};

	regulator-vsys-io-1v8 {
		compatible = "regulator-fixed";
		regulator-name = "vsys_io_1v8";
		regulator-min-microvolt = <0x1b7740>;
		regulator-max-microvolt = <0x1b7740>;
		regulator-always-on;
		regulator-boot-on;
		phandle = <0x2c>;
	};

	regulator-vsys-io-1v2 {
		compatible = "regulator-fixed";
		regulator-name = "vsys_io_1v2";
		regulator-min-microvolt = <0x124f80>;
		regulator-max-microvolt = <0x124f80>;
		regulator-always-on;
		regulator-boot-on;
		phandle = <0x33>;
	};

	sound {
		compatible = "simple-audio-card";
		simple-audio-card,name = "J722S-EVM";
		simple-audio-card,widgets = "Headphone\0Headphone Jack\0Line\0Line In\0Microphone\0Microphone Jack";
		simple-audio-card,routing = "Headphone Jack\0HPLOUT\0Headphone Jack\0HPROUT\0LINE1L\0Line In\0LINE1R\0Line In\0MIC3R\0Microphone Jack\0Microphone Jack\0Mic Bias";
		simple-audio-card,format = "dsp_b";
		simple-audio-card,bitclock-master = <0x6e>;
		simple-audio-card,frame-master = <0x6e>;
		simple-audio-card,bitclock-inversion;
		phandle = <0x126>;

		simple-audio-card,cpu {
			sound-dai = <0x6f>;
		};

		simple-audio-card,codec {
			sound-dai = <0x70>;
			clocks = <0x71>;
			phandle = <0x6e>;
		};
	};

	can-phy0 {
		compatible = "ti,tcan1042";
		#phy-cells = <0x00>;
		max-bitrate = <0x4c4b40>;
		pinctrl-names = "default";
		pinctrl-0 = <0x72>;
		standby-gpios = <0x73 0x0c 0x00>;
		phandle = <0x0f>;
	};

	can-phy1 {
		compatible = "ti,tcan1042";
		#phy-cells = <0x00>;
		max-bitrate = <0x4c4b40>;
		phandle = <0x11>;
	};

	can-phy2 {
		compatible = "ti,tcan1042";
		#phy-cells = <0x00>;
		max-bitrate = <0x4c4b40>;
		standby-gpios = <0x58 0x11 0x00>;
		phandle = <0x44>;
	};

	connector-hdmi {
		compatible = "hdmi-connector";
		label = "hdmi";
		type = "a";
		phandle = <0x127>;

		port {

			endpoint {
				remote-endpoint = <0x74>;
				phandle = <0x31>;
			};
		};
	};

	clock-edp0-refclk {
		#clock-cells = <0x00>;
		compatible = "fixed-clock";
		clock-frequency = <0x124f800>;
		phandle = <0x32>;
	};

	regulator-dp0-prw {
		compatible = "regulator-fixed";
		regulator-name = "dp0-pwr";
		regulator-min-microvolt = <0x325aa0>;
		regulator-max-microvolt = <0x325aa0>;
		gpio = <0x2f 0x02 0x00>;
		enable-active-high;
		regulator-always-on;
		phandle = <0x75>;
	};

	connector-dp0 {
		compatible = "dp-connector";
		label = "DP0";
		type = "full-size";
		dp-pwr-supply = <0x75>;
		phandle = <0x128>;

		port {

			endpoint {
				remote-endpoint = <0x76>;
				phandle = <0x35>;
			};
		};
	};

	__symbols__ {
		cluster0 = "/cpus/cpu-map/cluster0";
		cpu0 = "/cpus/cpu@0";
		cpu1 = "/cpus/cpu@1";
		cpu2 = "/cpus/cpu@2";
		cpu3 = "/cpus/cpu@3";
		l2_0 = "/l2-cache0";
		psci = "/firmware/psci";
		a53_timer0 = "/timer-cl0-cpu0";
		pmu = "/pmu";
		cbass_main = "/bus@f0000";
		cbass_mcu = "/bus@f0000/bus@4000000";
		mcu_ram = "/bus@f0000/bus@4000000/sram@79100000";
		mcu_pmx0 = "/bus@f0000/bus@4000000/pinctrl@4084000";
		mcu_pmx_range = "/bus@f0000/bus@4000000/pinctrl@4084000/gpio-range";
		mcu_i2c0_pins_default = "/bus@f0000/bus@4000000/pinctrl@4084000/mcu-i2c0-default-pins";
		mcu_mcan0_pins_default = "/bus@f0000/bus@4000000/pinctrl@4084000/mcu-mcan0-default-pins";
		mcu_mcan1_pins_default = "/bus@f0000/bus@4000000/pinctrl@4084000/mcu-mcan1-default-pins";
		mcu_mcan0_gpio_pins_default = "/bus@f0000/bus@4000000/pinctrl@4084000/mcu-mcan0-gpio-default-pins";
		wkup_uart0_pins_default = "/bus@f0000/bus@4000000/pinctrl@4084000/wkup-uart0-default-pins";
		wkup_i2c0_pins_default = "/bus@f0000/bus@4000000/pinctrl@4084000/wkup-i2c0-default-pins";
		mcu_esm = "/bus@f0000/bus@4000000/esm@4100000";
		mcu_timer0 = "/bus@f0000/bus@4000000/timer@4800000";
		mcu_timer1 = "/bus@f0000/bus@4000000/timer@4810000";
		mcu_timer2 = "/bus@f0000/bus@4000000/timer@4820000";
		mcu_timer3 = "/bus@f0000/bus@4000000/timer@4830000";
		mcu_uart0 = "/bus@f0000/bus@4000000/serial@4a00000";
		mcu_i2c0 = "/bus@f0000/bus@4000000/i2c@4900000";
		mcu_spi0 = "/bus@f0000/bus@4000000/spi@4b00000";
		mcu_spi1 = "/bus@f0000/bus@4000000/spi@4b10000";
		mcu_gpio_intr = "/bus@f0000/bus@4000000/interrupt-controller@4210000";
		mcu_gpio0 = "/bus@f0000/bus@4000000/gpio@4201000";
		mcu_rti0 = "/bus@f0000/bus@4000000/watchdog@4880000";
		mcu_mcan0 = "/bus@f0000/bus@4000000/can@4e08000";
		mcu_mcan1 = "/bus@f0000/bus@4000000/can@4e18000";
		mcu_r5fss0 = "/bus@f0000/bus@4000000/r5fss@79000000";
		mcu_r5fss0_core0 = "/bus@f0000/bus@4000000/r5fss@79000000/r5f@79000000";
		cbass_wakeup = "/bus@f0000/bus@b00000";
		wkup_conf = "/bus@f0000/bus@b00000/bus@43000000";
		chipid = "/bus@f0000/bus@b00000/bus@43000000/chipid@14";
		opp_efuse_table = "/bus@f0000/bus@b00000/bus@43000000/syscon@18";
		cpsw_mac_syscon = "/bus@f0000/bus@b00000/bus@43000000/ethernet-mac-syscon@200";
		usb0_phy_ctrl = "/bus@f0000/bus@b00000/bus@43000000/syscon@4008";
		usb1_phy_ctrl = "/bus@f0000/bus@b00000/bus@43000000/syscon@4018";
		ddr_pmctrl = "/bus@f0000/bus@b00000/bus@43000000/syscon@80d0";
		canuart_wake = "/bus@f0000/bus@b00000/bus@43000000/syscon@18300";
		pcie0_ctrl = "/bus@f0000/bus@b00000/bus@43000000/pcie0-ctrl@4070";
		wkup_uart0 = "/bus@f0000/bus@b00000/target-module@2b300050/serial@0";
		wkup_i2c0 = "/bus@f0000/bus@b00000/i2c@2b200000";
		tps65224 = "/bus@f0000/bus@b00000/i2c@2b200000/pmic@48";
		buck1 = "/bus@f0000/bus@b00000/i2c@2b200000/pmic@48/regulators/buck1";
		buck2 = "/bus@f0000/bus@b00000/i2c@2b200000/pmic@48/regulators/buck2";
		buck3 = "/bus@f0000/bus@b00000/i2c@2b200000/pmic@48/regulators/buck3";
		buck4 = "/bus@f0000/bus@b00000/i2c@2b200000/pmic@48/regulators/buck4";
		ldo1 = "/bus@f0000/bus@b00000/i2c@2b200000/pmic@48/regulators/ldo1";
		ldo2 = "/bus@f0000/bus@b00000/i2c@2b200000/pmic@48/regulators/ldo2";
		ldo3 = "/bus@f0000/bus@b00000/i2c@2b200000/pmic@48/regulators/ldo3";
		wkup_rtc0 = "/bus@f0000/bus@b00000/rtc@2b1f0000";
		wkup_rti0 = "/bus@f0000/bus@b00000/watchdog@2b000000";
		wkup_vtm0 = "/bus@f0000/bus@b00000/temperature-sensor@b00000";
		wkup_r5fss0 = "/bus@f0000/bus@b00000/r5fss@78000000";
		wkup_r5fss0_core0 = "/bus@f0000/bus@b00000/r5fss@78000000/r5f@78000000";
		oc_sram = "/bus@f0000/sram@70000000";
		gic500 = "/bus@f0000/interrupt-controller@1800000";
		gic_its = "/bus@f0000/interrupt-controller@1800000/msi-controller@1820000";
		main_conf = "/bus@f0000/bus@100000";
		phy_gmii_sel = "/bus@f0000/bus@100000/phy@4044";
		epwm_tbclk = "/bus@f0000/bus@100000/clock-controller@4130";
		dss_oldi_io_ctrl = "/bus@f0000/bus@100000/dss-oldi-io-ctrl@8600";
		serdes_ln_ctrl = "/bus@f0000/bus@100000/mux-controller@4080";
		audio_refclk1 = "/bus@f0000/bus@100000/clock@82e4";
		dmss = "/bus@f0000/bus@48000000";
		secure_proxy_main = "/bus@f0000/bus@48000000/mailbox@4d000000";
		inta_main_dmss = "/bus@f0000/bus@48000000/interrupt-controller@48000000";
		main_bcdma = "/bus@f0000/bus@48000000/dma-controller@485c0100";
		main_pktdma = "/bus@f0000/bus@48000000/dma-controller@485c0000";
		dmss_csi = "/bus@f0000/bus@4e000000";
		inta_main_dmss_csi = "/bus@f0000/bus@4e000000/interrupt-controller@4e400000";
		main_bcdma_csi = "/bus@f0000/bus@4e000000/dma-controller@4e230000";
		dmsc = "/bus@f0000/system-controller@44043000";
		k3_pds = "/bus@f0000/system-controller@44043000/power-controller";
		k3_clks = "/bus@f0000/system-controller@44043000/clock-controller";
		k3_reset = "/bus@f0000/system-controller@44043000/reset-controller";
		crypto = "/bus@f0000/crypto@40900000";
		crc = "/bus@f0000/crc@30300000";
		secure_proxy_sa3 = "/bus@f0000/mailbox@43600000";
		main_pmx0 = "/bus@f0000/pinctrl@f4000";
		main_pmx0_range = "/bus@f0000/pinctrl@f4000/gpio-range";
		main_mcan0_pins_default = "/bus@f0000/pinctrl@f4000/main-mcan0-default-pins";
		main_i2c0_pins_default = "/bus@f0000/pinctrl@f4000/main-i2c0-default-pins";
		main_i2c1_pins_default = "/bus@f0000/pinctrl@f4000/main-i2c1-default-pins";
		main_i2c2_pins_default = "/bus@f0000/pinctrl@f4000/main-i2c2-default-pins";
		main_uart0_pins_default = "/bus@f0000/pinctrl@f4000/main-uart0-default-pins";
		main_uart5_pins_default = "/bus@f0000/pinctrl@f4000/main-uart5-default-pins";
		vdd_sd_dv_pins_default = "/bus@f0000/pinctrl@f4000/vdd-sd-dv-default-pins";
		main_mmc1_pins_default = "/bus@f0000/pinctrl@f4000/main-mmc1-default-pins";
		mdio_pins_default = "/bus@f0000/pinctrl@f4000/mdio-default-pins";
		ospi0_pins_default = "/bus@f0000/pinctrl@f4000/ospi0-default-pins";
		rgmii1_pins_default = "/bus@f0000/pinctrl@f4000/rgmii1-default-pins";
		main_usb1_pins_default = "/bus@f0000/pinctrl@f4000/main-usb1-default-pins";
		main_mcasp1_pins_default = "/bus@f0000/pinctrl@f4000/main-mcasp1-default-pins";
		audio_ext_refclk1_pins_default = "/bus@f0000/pinctrl@f4000/audio-ext-refclk1-default-pins";
		pmic_irq_pins_default = "/bus@f0000/pinctrl@f4000/pmic-irq-default-pins";
		main_gpio0_ioexp_intr_pins_default = "/bus@f0000/pinctrl@f4000/main-gpio0-ioexp-intr-default-pins";
		main_dpi_pins_default = "/bus@f0000/pinctrl@f4000/main-dpi-default-pins";
		main_esm = "/bus@f0000/esm@420000";
		main_timer0 = "/bus@f0000/timer@2400000";
		main_timer1 = "/bus@f0000/timer@2410000";
		main_timer2 = "/bus@f0000/timer@2420000";
		main_timer3 = "/bus@f0000/timer@2430000";
		main_timer4 = "/bus@f0000/timer@2440000";
		main_timer5 = "/bus@f0000/timer@2450000";
		main_timer6 = "/bus@f0000/timer@2460000";
		main_timer7 = "/bus@f0000/timer@2470000";
		main_uart0 = "/bus@f0000/serial@2800000";
		main_uart1 = "/bus@f0000/serial@2810000";
		main_uart2 = "/bus@f0000/serial@2820000";
		main_uart3 = "/bus@f0000/serial@2830000";
		main_uart4 = "/bus@f0000/serial@2840000";
		main_uart5 = "/bus@f0000/serial@2850000";
		main_uart6 = "/bus@f0000/serial@2860000";
		main_i2c0 = "/bus@f0000/i2c@20000000";
		exp1 = "/bus@f0000/i2c@20000000/gpio@23";
		p01_hog = "/bus@f0000/i2c@20000000/gpio@23/p01-hog";
		p02_hog = "/bus@f0000/i2c@20000000/gpio@23/p02-hog";
		p13_hog = "/bus@f0000/i2c@20000000/gpio@23/p13-hog";
		tlv320aic3106 = "/bus@f0000/i2c@20000000/audio-codec@1b";
		main_i2c1 = "/bus@f0000/i2c@20010000";
		exp2 = "/bus@f0000/i2c@20010000/gpio@20";
		sii9022 = "/bus@f0000/i2c@20010000/bridge-hdmi@3b";
		hdmi_tx_ports = "/bus@f0000/i2c@20010000/bridge-hdmi@3b/ports";
		sii9022_in = "/bus@f0000/i2c@20010000/bridge-hdmi@3b/ports/port@0/endpoint";
		sii9022_out = "/bus@f0000/i2c@20010000/bridge-hdmi@3b/ports/port@1/endpoint";
		dsi_edp_bridge = "/bus@f0000/i2c@20010000/dsi-edp-bridge@2c";
		dsi_edp_bridge_ports = "/bus@f0000/i2c@20010000/dsi-edp-bridge@2c/ports";
		dp0_in = "/bus@f0000/i2c@20010000/dsi-edp-bridge@2c/ports/port@0/endpoint";
		dp0_out = "/bus@f0000/i2c@20010000/dsi-edp-bridge@2c/ports/port@1/endpoint";
		main_i2c2 = "/bus@f0000/i2c@20020000";
		pca9543_0 = "/bus@f0000/i2c@20020000/i2c-mux@70";
		pca9543_1 = "/bus@f0000/i2c@20020000/i2c-mux@71";
		main_i2c3 = "/bus@f0000/i2c@20030000";
		main_spi0 = "/bus@f0000/spi@20100000";
		main_spi1 = "/bus@f0000/spi@20110000";
		main_spi2 = "/bus@f0000/spi@20120000";
		main_gpio_intr = "/bus@f0000/interrupt-controller@a00000";
		main_gpio0 = "/bus@f0000/gpio@600000";
		main_gpio1 = "/bus@f0000/gpio@601000";
		sdhci0 = "/bus@f0000/mmc@fa10000";
		sdhci1 = "/bus@f0000/mmc@fa00000";
		sdhci2 = "/bus@f0000/mmc@fa20000";
		usbss0 = "/bus@f0000/usb@f900000";
		usb0 = "/bus@f0000/usb@f900000/usb@31000000";
		fss = "/bus@f0000/bus@fc00000";
		ospi0 = "/bus@f0000/bus@fc00000/spi@fc40000";
		ospi0_nand = "/bus@f0000/bus@fc00000/spi@fc40000/nand@0";
		cpsw3g = "/bus@f0000/ethernet@8000000";
		cpsw_port1 = "/bus@f0000/ethernet@8000000/ethernet-ports/port@1";
		cpsw_port2 = "/bus@f0000/ethernet@8000000/ethernet-ports/port@2";
		cpsw3g_mdio = "/bus@f0000/ethernet@8000000/mdio@f00";
		cpsw3g_phy0 = "/bus@f0000/ethernet@8000000/mdio@f00/ethernet-phy@0";
		gpu = "/bus@f0000/gpu@fd80000";
		hwspinlock = "/bus@f0000/spinlock@2a000000";
		timesync_router = "/bus@f0000/mux-controller@a40000";
		mailbox0_cluster0 = "/bus@f0000/mailbox@29000000";
		mbox_wkup_r5_0 = "/bus@f0000/mailbox@29000000/mbox-wkup-r5-0";
		mailbox0_cluster1 = "/bus@f0000/mailbox@29010000";
		mbox_mcu_r5_0 = "/bus@f0000/mailbox@29010000/mbox-mcu-r5-0";
		mailbox0_cluster2 = "/bus@f0000/mailbox@29020000";
		mbox_c7x_0 = "/bus@f0000/mailbox@29020000/mbox-c7x-0";
		mailbox0_cluster3 = "/bus@f0000/mailbox@29030000";
		mbox_main_r5_0 = "/bus@f0000/mailbox@29030000/mbox-main-r5-0";
		mbox_c7x_1 = "/bus@f0000/mailbox@29030000/mbox-c7x-1";
		ecap0 = "/bus@f0000/pwm@23100000";
		ecap1 = "/bus@f0000/pwm@23110000";
		ecap2 = "/bus@f0000/pwm@23120000";
		eqep0 = "/bus@f0000/counter@23200000";
		eqep1 = "/bus@f0000/counter@23210000";
		eqep2 = "/bus@f0000/counter@23220000";
		main_mcan0 = "/bus@f0000/can@20701000";
		main_mcan1 = "/bus@f0000/can@20711000";
		main_rti0 = "/bus@f0000/watchdog@e000000";
		main_rti1 = "/bus@f0000/watchdog@e010000";
		main_rti2 = "/bus@f0000/watchdog@e020000";
		main_rti3 = "/bus@f0000/watchdog@e030000";
		main_rti15 = "/bus@f0000/watchdog@e0f0000";
		epwm0 = "/bus@f0000/pwm@23000000";
		epwm1 = "/bus@f0000/pwm@23010000";
		epwm2 = "/bus@f0000/pwm@23020000";
		mcasp0 = "/bus@f0000/audio-controller@2b00000";
		mcasp1 = "/bus@f0000/audio-controller@2b10000";
		mcasp2 = "/bus@f0000/audio-controller@2b20000";
		ti_csi2rx0 = "/bus@f0000/ticsi2rx@30102000";
		cdns_csi2rx0 = "/bus@f0000/ticsi2rx@30102000/csi-bridge@30101000";
		csi0_port0 = "/bus@f0000/ticsi2rx@30102000/csi-bridge@30101000/ports/port@0";
		csi0_port1 = "/bus@f0000/ticsi2rx@30102000/csi-bridge@30101000/ports/port@1";
		csi0_port2 = "/bus@f0000/ticsi2rx@30102000/csi-bridge@30101000/ports/port@2";
		csi0_port3 = "/bus@f0000/ticsi2rx@30102000/csi-bridge@30101000/ports/port@3";
		csi0_port4 = "/bus@f0000/ticsi2rx@30102000/csi-bridge@30101000/ports/port@4";
		dphy0 = "/bus@f0000/phy@30110000";
		dss0 = "/bus@f0000/dss@30200000";
		oldi0_dss0 = "/bus@f0000/dss@30200000/oldi-transmitters/oldi@0";
		oldi0_dss0_ports = "/bus@f0000/dss@30200000/oldi-transmitters/oldi@0/ports";
		oldi1_dss0 = "/bus@f0000/dss@30200000/oldi-transmitters/oldi@1";
		oldi1_dss0_ports = "/bus@f0000/dss@30200000/oldi-transmitters/oldi@1/ports";
		dss0_ports = "/bus@f0000/dss@30200000/ports";
		dss1 = "/bus@f0000/dss@30220000";
		oldi1_dss1 = "/bus@f0000/dss@30220000/oldi-transmitters/oldi@1";
		oldi1_dss1_ports = "/bus@f0000/dss@30220000/oldi-transmitters/oldi@1/ports";
		dss1_ports = "/bus@f0000/dss@30220000/ports";
		dss1_dpi0_out = "/bus@f0000/dss@30220000/ports/port@0/endpoint";
		dss1_dpi1_out = "/bus@f0000/dss@30220000/ports/port@1/endpoint";
		dphy_tx0 = "/bus@f0000/phy@301c0000";
		dsi0 = "/bus@f0000/dsi@30500000";
		dsi0_out = "/bus@f0000/dsi@30500000/ports/port@0/endpoint";
		dsi0_in = "/bus@f0000/dsi@30500000/ports/port@1/endpoint";
		vpu = "/bus@f0000/video-codec@30210000";
		vpu_opp_table = "/bus@f0000/video-codec@30210000/opp-table";
		serdes_wiz0 = "/bus@f0000/phy@f000000";
		serdes0 = "/bus@f0000/phy@f000000/serdes@f000000";
		serdes0_usb_link = "/bus@f0000/phy@f000000/serdes@f000000/phy@0";
		serdes_wiz1 = "/bus@f0000/phy@f010000";
		serdes1 = "/bus@f0000/phy@f010000/serdes@f010000";
		serdes1_pcie_link = "/bus@f0000/phy@f010000/serdes@f010000/phy@0";
		pcie0_rc = "/bus@f0000/pcie@f102000";
		usbss1 = "/bus@f0000/usb@f920000";
		usb1 = "/bus@f0000/usb@f920000/usb@31200000";
		ti_csi2rx1 = "/bus@f0000/ticsi2rx@30122000";
		cdns_csi2rx1 = "/bus@f0000/ticsi2rx@30122000/csi-bridge@30121000";
		csi1_port0 = "/bus@f0000/ticsi2rx@30122000/csi-bridge@30121000/ports/port@0";
		csi1_port1 = "/bus@f0000/ticsi2rx@30122000/csi-bridge@30121000/ports/port@1";
		csi1_port2 = "/bus@f0000/ticsi2rx@30122000/csi-bridge@30121000/ports/port@2";
		csi1_port3 = "/bus@f0000/ticsi2rx@30122000/csi-bridge@30121000/ports/port@3";
		csi1_port4 = "/bus@f0000/ticsi2rx@30122000/csi-bridge@30121000/ports/port@4";
		ti_csi2rx2 = "/bus@f0000/ticsi2rx@30142000";
		cdns_csi2rx2 = "/bus@f0000/ticsi2rx@30142000/csi-bridge@30141000";
		csi2_port0 = "/bus@f0000/ticsi2rx@30142000/csi-bridge@30141000/ports/port@0";
		csi2_port1 = "/bus@f0000/ticsi2rx@30142000/csi-bridge@30141000/ports/port@1";
		csi2_port2 = "/bus@f0000/ticsi2rx@30142000/csi-bridge@30141000/ports/port@2";
		csi2_port3 = "/bus@f0000/ticsi2rx@30142000/csi-bridge@30141000/ports/port@3";
		csi2_port4 = "/bus@f0000/ticsi2rx@30142000/csi-bridge@30141000/ports/port@4";
		ti_csi2rx3 = "/bus@f0000/ticsi2rx@30162000";
		cdns_csi2rx3 = "/bus@f0000/ticsi2rx@30162000/csi-bridge@30161000";
		csi3_port0 = "/bus@f0000/ticsi2rx@30162000/csi-bridge@30161000/ports/port@0";
		csi3_port1 = "/bus@f0000/ticsi2rx@30162000/csi-bridge@30161000/ports/port@1";
		csi3_port2 = "/bus@f0000/ticsi2rx@30162000/csi-bridge@30161000/ports/port@2";
		csi3_port3 = "/bus@f0000/ticsi2rx@30162000/csi-bridge@30161000/ports/port@3";
		csi3_port4 = "/bus@f0000/ticsi2rx@30162000/csi-bridge@30161000/ports/port@4";
		dphy1 = "/bus@f0000/phy@30130000";
		dphy2 = "/bus@f0000/phy@30150000";
		dphy3 = "/bus@f0000/phy@30170000";
		main_r5fss0 = "/bus@f0000/r5fss@78400000";
		main_r5fss0_core0 = "/bus@f0000/r5fss@78400000/r5f@78400000";
		c7x_0 = "/bus@f0000/dsp@7e000000";
		c7x_1 = "/bus@f0000/dsp@7e200000";
		e5010 = "/bus@f0000/e5010@fd20000";
		dss0_vp1_clk = "/clock-divider-oldi-dss0";
		dss1_vp1_clk = "/clock-divider-oldi-dss1";
		thermal_zones = "/thermal-zones";
		main0_thermal = "/thermal-zones/main0-thermal";
		main0_crit = "/thermal-zones/main0-thermal/trips/main0-crit";
		main1_thermal = "/thermal-zones/main1-thermal";
		main1_crit = "/thermal-zones/main1-thermal/trips/main1-crit";
		main2_thermal = "/thermal-zones/main2-thermal";
		main2_crit = "/thermal-zones/main2-thermal/trips/main2-crit";
		serdes_refclk = "/clk-0";
		reserved_memory = "/reserved-memory";
		secure_tfa_ddr = "/reserved-memory/tfa@9e780000";
		secure_ddr = "/reserved-memory/optee@9e800000";
		wkup_r5fss0_core0_dma_memory_region = "/reserved-memory/r5f-dma-memory@a0000000";
		wkup_r5fss0_core0_memory_region = "/reserved-memory/r5f-memory@a0100000";
		mcu_r5fss0_core0_dma_memory_region = "/reserved-memory/mcu-r5fss-dma-memory-region@a1000000";
		mcu_r5fss0_core0_memory_region = "/reserved-memory/mcu-r5fss-memory-region@a1100000";
		main_r5fss0_core0_dma_memory_region = "/reserved-memory/main-r5fss-dma-memory-region@a2000000";
		main_r5fss0_core0_memory_region = "/reserved-memory/main-r5fss-memory-region@a2100000";
		c7x_0_dma_memory_region = "/reserved-memory/c7x-dma-memory@a3000000";
		c7x_0_memory_region = "/reserved-memory/c7x-memory@a3100000";
		c7x_1_dma_memory_region = "/reserved-memory/c7x-dma-memory@a4000000";
		c7x_1_memory_region = "/reserved-memory/c7x-memory@a4100000";
		rtos_ipc_memory_region = "/reserved-memory/ipc-memories@a5000000";
		vmain_pd = "/regulator-0";
		vsys_5v0 = "/regulator-vsys5v0";
		vdd_mmc1 = "/regulator-mmc1";
		vdd_sd_dv = "/regulator-TLV71033";
		vsys_io_3v3 = "/regulator-vsys-io-3v3";
		vsys_io_1v8 = "/regulator-vsys-io-1v8";
		vsys_io_1v2 = "/regulator-vsys-io-1v2";
		codec_audio = "/sound";
		sound_master = "/sound/simple-audio-card,codec";
		transceiver0 = "/can-phy0";
		transceiver1 = "/can-phy1";
		transceiver2 = "/can-phy2";
		hdmi0 = "/connector-hdmi";
		hdmi_connector_in = "/connector-hdmi/port/endpoint";
		edp0_refclk = "/clock-edp0-refclk";
		dp0_pwr_3v3 = "/regulator-dp0-prw";
		dp0 = "/connector-dp0";
		dp0_connector_in = "/connector-dp0/port/endpoint";
	};
};
